VERSION ""

NS_ :

BS_:

BU_: IAP ODS _4WD BCM HUD DATC MDPS AAF_Tester AEMC SMK _4WD EPB CUBIS MTS TMU EVP CGW TPMS LPI DI_BOX SPAS EMS LCA TCU IBOX FATC AFLS FPCM SCC AHLS AVM ABS SNV OPI PGS SAS AAF Dummy LDWS_LKAS LVR ESC PSB CLU ECS ACU REA

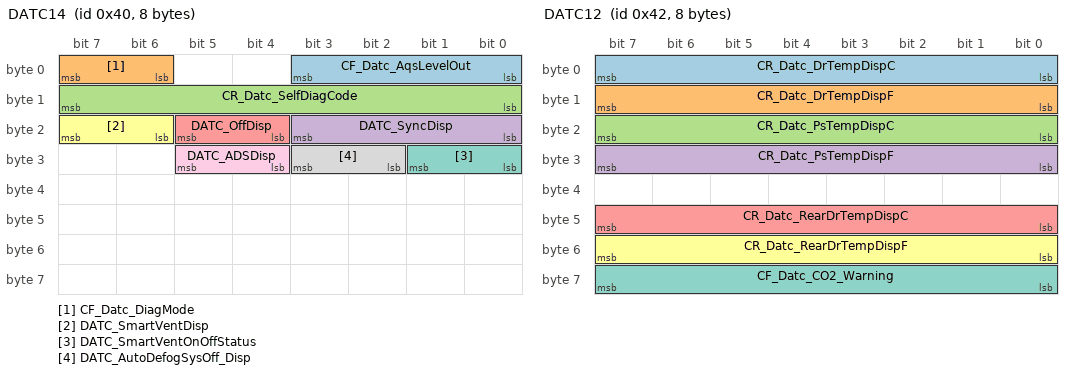
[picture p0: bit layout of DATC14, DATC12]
BO_ 64 DATC14: 8 DATC
 SG_ CF_Datc_AqsLevelOut : 0|4@1+ (1.0,0.0) [0.0|3.0] ""  CLU
 SG_ CF_Datc_DiagMode : 6|2@1+ (1.0,0.0) [0.0|3.0] ""  CLU
 SG_ CR_Datc_SelfDiagCode : 8|8@1+ (1.0,-1.0) [0.0|254.0] ""  CLU
 SG_ DATC_SyncDisp : 16|4@1+ (1.0,0.0) [0.0|3.0] ""  CLU
 SG_ DATC_OffDisp : 20|2@1+ (1.0,0.0) [0.0|3.0] ""  CLU
 SG_ DATC_SmartVentDisp : 22|2@1+ (1.0,0.0) [0.0|3.0] ""  CLU
 SG_ DATC_SmartVentOnOffStatus : 24|2@1+ (1.0,0.0) [0.0|3.0] ""  CLU
 SG_ DATC_AutoDefogSysOff_Disp : 26|2@1+ (1.0,0.0) [0.0|3.0] ""  CLU
 SG_ DATC_ADSDisp : 28|2@1+ (1.0,0.0) [0.0|3.0] ""  CLU

BO_ 66 DATC12: 8 DATC
 SG_ CR_Datc_DrTempDispC : 0|8@1+ (0.5,14.0) [15.0|32.0] "deg"  CLU,IBOX
 SG_ CR_Datc_DrTempDispF : 8|8@1+ (1.0,56.0) [58.0|90.0] "deg"  CLU,IBOX
 SG_ CR_Datc_PsTempDispC : 16|8@1+ (0.5,14.0) [15.0|32.0] "deg"  CLU,IBOX
 SG_ CR_Datc_PsTempDispF : 24|8@1+ (1.0,56.0) [58.0|90.0] "deg"  CLU,IBOX
 SG_ CR_Datc_RearDrTempDispC : 40|8@1+ (0.5,14.0) [15.0|32.0] "deg"  CLU
 SG_ CR_Datc_RearDrTempDispF : 48|8@1+ (1.0,58.0) [58.0|90.0] "deg"  CLU
 SG_ CF_Datc_CO2_Warning : 56|8@1+ (1.0,0.0) [0.0|3.0] ""  CLU

BO_ 67 DATC13: 8 DATC
 SG_ CF_Datc_TempDispUnit : 0|2@1+ (1.0,0.0) [0.0|3.0] ""  CLU,IBOX
 SG_ CF_Datc_ModDisp : 2|4@1+ (1.0,0.0) [0.0|15.0] ""  CLU
 SG_ CF_Datc_IonClean : 6|2@1+ (1.0,0.0) [0.0|3.0] ""  CLU
 SG_ CF_Datc_ChgReqDisp : 8|2@1+ (1.0,0.0) [0.0|3.0] ""  CLU
 SG_ CF_Datc_IntakeDisp : 10|2@1+ (1.0,0.0) [0.0|3.0] ""  CLU
 SG_ CF_Datc_AutoDisp : 12|2@1+ (1.0,0.0) [0.0|3.0] ""  CLU
 SG_ CF_Datc_FrDefLed : 14|2@1+ (1.0,0.0) [0.0|3.0] ""  CLU,IBOX
 SG_ CF_Datc_AutoDefogBlink : 16|2@1+ (1.0,0.0) [0.0|3.0] ""  CLU
 SG_ CF_Datc_ClmScanDisp : 18|2@1+ (1.0,0.0) [0.0|3.0] ""  CLU
 SG_ CF_Datc_AqsDisp : 20|2@1+ (1.0,0.0) [0.0|3.0] ""  CLU
 SG_ CF_Datc_AcDisp : 22|2@1+ (1.0,0.0) [0.0|3.0] ""  CLU
 SG_ CF_Datc_OpSts : 25|3@1+ (1.0,0.0) [0.0|7.0] ""  CLU
 SG_ CF_Mtc_MaxAcDisp : 28|2@1+ (1.0,0.0) [0.0|3.0] ""  CLU
 SG_ CF_Datc_DualDisp : 30|2@1+ (1.0,0.0) [0.0|3.0] ""  CLU
 SG_ CF_Datc_PwrInf : 32|4@1+ (1.0,0.0) [0.0|15.0] ""  CLU
 SG_ CF_Datc_RearManual : 38|2@1+ (1.0,0.0) [0.0|3.0] ""  CLU
 SG_ CF_Datc_RearAutoDisp : 40|2@1+ (1.0,0.0) [0.0|1.0] ""  CLU
 SG_ CF_Datc_RearOffDisp : 42|2@1+ (1.0,0.0) [0.0|3.0] ""  CLU
 SG_ CF_Datc_RearClimateScnDisp : 44|2@1+ (1.0,0.0) [0.0|3.0] ""  CLU
 SG_ CF_Datc_RearChgReqDisp : 46|2@1+ (1.0,0.0) [0.0|3.0] ""  CLU
 SG_ CF_Datc_RearModDisp : 48|4@1+ (1.0,0.0) [0.0|15.0] ""  CLU
 SG_ CF_Datc_RearBlwDisp : 52|4@1+ (1.0,0.0) [0.0|15.0] ""  CLU
 SG_ CF_Datc_PSModDisp : 56|4@1+ (1.0,0.0) [0.0|15.0] ""  CLU
 SG_ CF_Datc_FrontBlwDisp : 60|4@1+ (1.0,0.0) [0.0|15.0] ""  CLU,IBOX

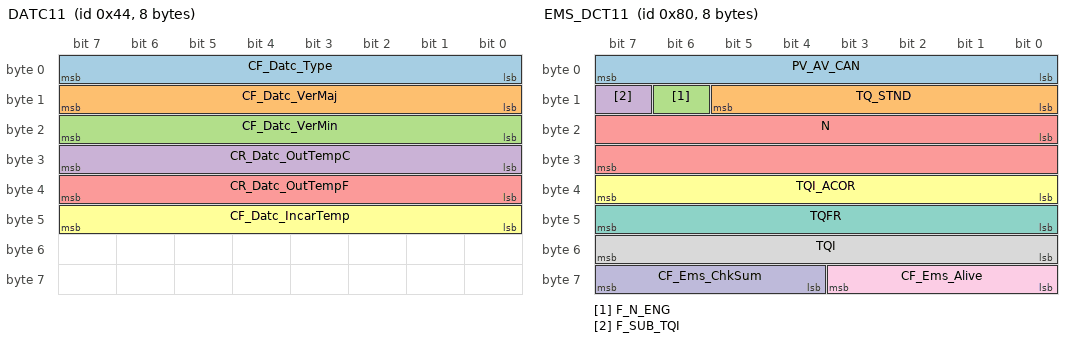
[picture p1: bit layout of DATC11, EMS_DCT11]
BO_ 68 DATC11: 8 DATC
 SG_ CF_Datc_Type : 0|8@1+ (1.0,0.0) [0.0|255.0] ""  CLU
 SG_ CF_Datc_VerMaj : 8|8@1+ (1.0,0.0) [0.0|255.0] ""  CLU
 SG_ CF_Datc_VerMin : 16|8@1+ (1.0,0.0) [0.0|255.0] ""  CLU
 SG_ CR_Datc_OutTempC : 24|8@1+ (0.5,-41.0) [-41.0|86.5] "deg"  CLU,FPCM
 SG_ CR_Datc_OutTempF : 32|8@1+ (1.0,-42.0) [-42.0|213.0] "deg"  CLU
 SG_ CF_Datc_IncarTemp : 40|8@1+ (0.5,-40.0) [-40.0|60.0] "deg"  BCM,CLU

BO_ 127 CGW5: 8 BCM
 SG_ C_StopLampLhOpenSts : 0|1@1+ (1.0,0.0) [0.0|1.0] ""  CLU
 SG_ C_StopLampRhOpenSts : 1|1@1+ (1.0,0.0) [0.0|1.0] ""  CLU
 SG_ C_HMSLOpenSts : 2|1@1+ (1.0,0.0) [0.0|1.0] ""  CLU
 SG_ C_HLampLowLhOpenSts : 3|1@1+ (1.0,0.0) [0.0|1.0] ""  CLU
 SG_ C_HLampLowRhOpenSts : 4|1@1+ (1.0,0.0) [0.0|1.0] ""  CLU
 SG_ C_HLampHighLhOpenSts : 5|1@1+ (1.0,0.0) [0.0|1.0] ""  CLU
 SG_ C_HLampHighRhOpenSts : 6|1@1+ (1.0,0.0) [0.0|1.0] ""  CLU
 SG_ C_DRLLampLhOpenSts : 7|1@1+ (1.0,0.0) [0.0|1.0] ""  CLU
 SG_ C_DRLLampRhOpenSts : 8|1@1+ (1.0,0.0) [0.0|1.0] ""  CLU
 SG_ C_RearFOGLhOpenSts : 9|1@1+ (1.0,0.0) [0.0|1.0] ""  CLU
 SG_ C_RearFOGRhOpenSts : 10|1@1+ (1.0,0.0) [0.0|1.0] ""  CLU
 SG_ C_FrontFOGLhOpenSts : 11|1@1+ (1.0,0.0) [0.0|1.0] ""  CLU
 SG_ C_FrontFOGRhOpenSts : 12|1@1+ (1.0,0.0) [0.0|1.0] ""  CLU
 SG_ C_RearEXTTailLhOpenSts : 13|1@1+ (1.0,0.0) [0.0|1.0] ""  CLU
 SG_ C_RearEXTTailRhOpenSts : 14|1@1+ (1.0,0.0) [0.0|1.0] ""  CLU
 SG_ C_FrontEXTTailLhOpenSts : 15|1@1+ (1.0,0.0) [0.0|1.0] ""  CLU
 SG_ C_FrontEXTTailRhOpenSts : 16|1@1+ (1.0,0.0) [0.0|1.0] ""  CLU
 SG_ C_RearTSIGLhOpenSts : 17|1@1+ (1.0,0.0) [0.0|1.0] ""  CLU
 SG_ C_RearTSIGRhOpenSts : 18|1@1+ (1.0,0.0) [0.0|1.0] ""  CLU
 SG_ C_FrontTSIGLhOpenSts : 19|1@1+ (1.0,0.0) [0.0|1.0] ""  CLU
 SG_ C_FrontTSIGRhOpenSts : 20|1@1+ (1.0,0.0) [0.0|1.0] ""  CLU
 SG_ C_SBendingLhOpenSts : 21|1@1+ (1.0,0.0) [0.0|1.0] ""  CLU
 SG_ C_SBendingRhOpenSts : 22|1@1+ (1.0,0.0) [0.0|1.0] ""  CLU
 SG_ C_LicensePlateLhOpenSts : 23|1@1+ (1.0,0.0) [0.0|1.0] ""  CLU
 SG_ C_LicensePlateRhOpenSts : 24|1@1+ (1.0,0.0) [0.0|1.0] ""  CLU

BO_ 128 EMS_DCT11: 8 EMS
 SG_ PV_AV_CAN : 0|8@1+ (0.3906,0.0) [0.0|99.603] "%"  TCU
 SG_ TQ_STND : 8|6@1+ (10.0,0.0) [0.0|630.0] "Nm"  TCU
 SG_ F_N_ENG : 14|1@1+ (1.0,0.0) [0.0|1.0] ""  TCU
 SG_ F_SUB_TQI : 15|1@1+ (1.0,0.0) [0.0|1.0] ""  TCU
 SG_ N : 16|16@1+ (0.25,0.0) [0.0|16383.75] "rpm"  TCU
 SG_ TQI_ACOR : 32|8@1+ (0.390625,0.0) [0.0|99.6094] "%"  IBOX,TCU
 SG_ TQFR : 40|8@1+ (0.390625,0.0) [0.0|99.6094] "%"  TCU
 SG_ TQI : 48|8@1+ (0.390625,0.0) [0.0|99.609375] "%"  TCU
 SG_ CF_Ems_Alive : 56|4@1+ (1.0,0.0) [0.0|15.0] ""  TCU
 SG_ CF_Ems_ChkSum : 60|4@1+ (1.0,0.0) [0.0|15.0] ""  TCU

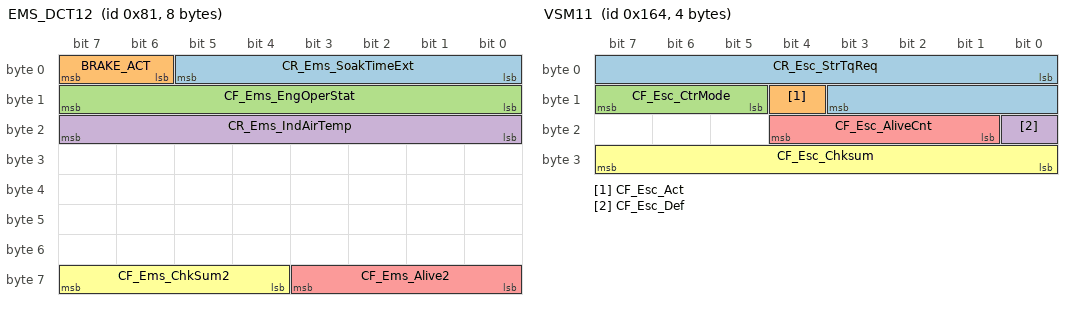
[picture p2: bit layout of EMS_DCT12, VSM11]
BO_ 129 EMS_DCT12: 8 EMS
 SG_ CR_Ems_SoakTimeExt : 0|6@1+ (5.0,0.0) [0.0|315.0] "Min"  TCU
 SG_ BRAKE_ACT : 6|2@1+ (1.0,0.0) [0.0|3.0] ""  TCU
 SG_ CF_Ems_EngOperStat : 8|8@1+ (1.0,0.0) [0.0|255.0] ""  TCU
 SG_ CR_Ems_IndAirTemp : 16|8@1+ (0.75,-48.0) [-48.0|143.25] "deg"  TCU
 SG_ CF_Ems_Alive2 : 56|4@1+ (1.0,0.0) [0.0|15.0] ""  TCU
 SG_ CF_Ems_ChkSum2 : 60|4@1+ (1.0,0.0) [0.0|15.0] ""  TCU

BO_ 339 TCS11: 8 ESC
 SG_ TCS_REQ : 0|1@1+ (1.0,0.0) [0.0|1.0] ""  _4WD,EMS,EPB,TCU
 SG_ MSR_C_REQ : 1|1@1+ (1.0,0.0) [0.0|1.0] ""  EMS,EPB,SCC,TCU
 SG_ TCS_PAS : 2|1@1+ (1.0,0.0) [0.0|1.0] ""  _4WD,CLU,EMS,SCC,SPAS,TCU
 SG_ TCS_GSC : 3|1@1+ (1.0,0.0) [0.0|1.0] ""  _4WD,EMS,TCU
 SG_ CF_Esc_LimoInfo : 4|2@1+ (1.0,0.0) [0.0|3.0] ""  _4WD,SCC
 SG_ ABS_DIAG : 6|1@1+ (1.0,0.0) [0.0|1.0] ""  _4WD,CLU,EMS,EPB
 SG_ ABS_DEF : 7|1@1+ (1.0,0.0) [0.0|1.0] ""  _4WD,ACU,ECS,EMS,EPB,SCC,SPAS,TCU
 SG_ TCS_DEF : 8|1@1+ (1.0,0.0) [0.0|1.0] ""  _4WD,EMS,EPB,SCC,SPAS,TCU
 SG_ TCS_CTL : 9|1@1+ (1.0,0.0) [0.0|1.0] ""  _4WD,EMS,EPB,SCC,SPAS,TCU
 SG_ ABS_ACT : 10|1@1+ (1.0,0.0) [0.0|1.0] ""  _4WD,ACU,ECS,EMS,EPB,LDWS_LKAS,SCC,SPAS,TCU
 SG_ EBD_DEF : 11|1@1+ (1.0,0.0) [0.0|1.0] ""  _4WD,EMS,EPB,SPAS,TCU
 SG_ ESP_PAS : 12|1@1+ (1.0,0.0) [0.0|1.0] ""  _4WD,ACU,CLU,EMS,EPB,LDWS_LKAS,SCC,TCU
 SG_ ESP_DEF : 13|1@1+ (1.0,0.0) [0.0|1.0] ""  _4WD,ACU,ECS,EMS,EPB,LDWS_LKAS,SCC,TCU
 SG_ ESP_CTL : 14|1@1+ (1.0,0.0) [0.0|1.0] ""  _4WD,ACU,ECS,EMS,EPB,LDWS_LKAS,SCC,SPAS,TCU
 SG_ TCS_MFRN : 15|1@1+ (1.0,0.0) [0.0|1.0] ""  EMS,EPB,TCU
 SG_ DBC_CTL : 16|1@1+ (1.0,0.0) [0.0|1.0] ""  _4WD,EMS,EPB
 SG_ DBC_PAS : 17|1@1+ (1.0,0.0) [0.0|1.0] ""  _4WD,EMS,EPB
 SG_ DBC_DEF : 18|1@1+ (1.0,0.0) [0.0|1.0] ""  _4WD,EMS,EPB
 SG_ HAC_CTL : 19|1@1+ (1.0,0.0) [0.0|1.0] ""  _4WD,CLU,EMS,EPB,TCU
 SG_ HAC_PAS : 20|1@1+ (1.0,0.0) [0.0|1.0] ""  _4WD,CLU,EMS,EPB,TCU
 SG_ HAC_DEF : 21|1@1+ (1.0,0.0) [0.0|1.0] ""  _4WD,CLU,EMS,EPB,TCU
 SG_ ESS_STAT : 22|2@1+ (1.0,0.0) [0.0|3.0] ""  _4WD,BCM,CLU,EMS,EPB
 SG_ TQI_TCS : 24|8@1+ (0.390625,0.0) [0.0|99.609375] "%"  EMS,EPB,TCU
 SG_ TQI_MSR : 32|8@1+ (0.390625,0.0) [0.0|99.609375] "%"  EMS,EPB,TCU
 SG_ TQI_SLW_TCS : 40|8@1+ (0.390625,0.0) [0.0|99.609375] "%"  EMS,EPB,TCU
 SG_ CF_Esc_BrkCtl : 48|1@1+ (1.0,0.0) [0.0|1.0] ""  EMS
 SG_ BLA_CTL : 49|2@1+ (1.0,0.0) [0.0|3.0] ""  BCM,CGW,CLU
 SG_ AliveCounter_TCS1 : 52|4@1+ (1.0,0.0) [0.0|14.0] ""  EMS,EPB,LDWS_LKAS
 SG_ CheckSum_TCS1 : 56|8@1+ (1.0,0.0) [0.0|255.0] ""  EMS,EPB,LDWS_LKAS

BO_ 356 VSM11: 4 ESC
 SG_ CR_Esc_StrTqReq : 0|12@1+ (0.01,-20.48) [-20.48|20.47] "Nm"  MDPS
 SG_ CF_Esc_Act : 12|1@1+ (1.0,0.0) [0.0|1.0] ""  LDWS_LKAS,MDPS
 SG_ CF_Esc_CtrMode : 13|3@1+ (1.0,0.0) [0.0|7.0] ""  MDPS
 SG_ CF_Esc_Def : 16|1@1+ (1.0,0.0) [0.0|1.0] ""  MDPS
 SG_ CF_Esc_AliveCnt : 17|4@1+ (1.0,0.0) [0.0|15.0] ""  LDWS_LKAS,MDPS
 SG_ CF_Esc_Chksum : 24|8@1+ (1.0,0.0) [0.0|255.0] ""  LDWS_LKAS,MDPS

BO_ 399 EMS_H12: 8 EMS
 SG_ R_TqAcnApvC : 0|8@1+ (0.2,0.0) [0.0|51.0] "Nm"  DATC,IBOX
 SG_ R_PAcnC : 8|8@1+ (125.0,0.0) [0.0|31875.0] "hPa"  DATC,IBOX
 SG_ TQI_B : 16|8@1+ (0.390625,0.0) [0.0|99.609375] "%"  ABS,ESC,IBOX
 SG_ SLD_VS : 24|8@1+ (1.0,0.0) [0.0|255.0] "km/h"  CLU,IBOX
 SG_ CF_CdaStat : 32|3@1+ (1.0,0.0) [0.0|7.0] ""  AEMC,IBOX,TCU
 SG_ CF_Ems_IsgStat : 35|3@1+ (1.0,0.0) [0.0|7.0] ""  ABS,BCM,CLU,DATC,EPB,ESC,IBOX,LDWS_LKAS,MDPS,SMK,TCU
 SG_ CF_Ems_OilChg : 38|1@1+ (1.0,0.0) [0.0|1.0] ""  CLU,IBOX
 SG_ CF_Ems_EtcLimpMod : 39|1@1+ (1.0,0.0) [0.0|1.0] ""  CLU,IBOX
 SG_ R_NEngIdlTgC : 40|8@1+ (10.0,0.0) [0.0|2550.0] "rpm"  DATC,IBOX,TCU
 SG_ CF_Ems_UpTarGr : 48|1@1+ (1.0,0.0) [0.0|1.0] ""  CLU,IBOX
 SG_ CF_Ems_DownTarGr : 49|1@1+ (1.0,0.0) [0.0|1.0] ""  CLU,IBOX
 SG_ CF_Ems_DesCurGr : 50|4@1+ (1.0,0.0) [0.0|15.0] ""  CLU,IBOX
 SG_ CF_Ems_SldAct : 54|1@1+ (1.0,0.0) [0.0|1.0] ""  CLU,IBOX
 SG_ CF_Ems_SldPosAct : 55|1@1+ (1.0,0.0) [0.0|1.0] ""  CLU,IBOX
 SG_ CF_Ems_HPresStat : 56|1@1+ (1.0,0.0) [0.0|1.0] ""  IBOX,TCU
 SG_ CF_Ems_IsgBuz : 57|1@1+ (1.0,0.0) [0.0|1.0] ""  CLU,IBOX
 SG_ CF_Ems_IdlStpFCO : 58|1@1+ (1.0,0.0) [0.0|1.0] ""  CLU,IBOX
 SG_ CF_Ems_FCopen : 59|1@1+ (1.0,0.0) [0.0|1.0] ""  CLU,IBOX
 SG_ CF_Ems_ActEcoAct : 60|1@1+ (1.0,0.0) [0.0|1.0] ""  CLU,IBOX,TCU
 SG_ CF_Ems_EngRunNorm : 61|1@1+ (1.0,0.0) [0.0|1.0] ""  ABS,ESC,IBOX,TCU
 SG_ CF_Ems_IsgStat2 : 62|2@1+ (2.0,0.0) [0.0|3.0] ""  CLU,IBOX,TCU

BO_ 447 ???: 8 ???

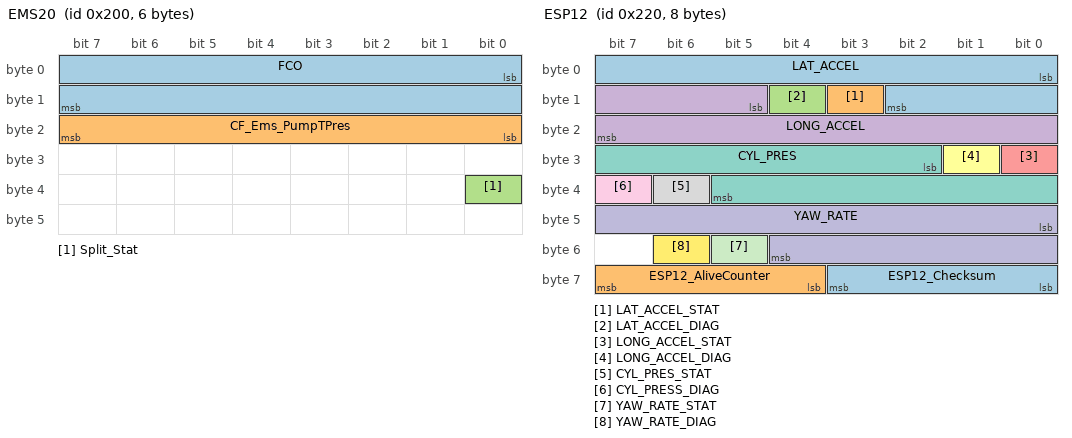
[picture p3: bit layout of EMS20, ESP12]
BO_ 512 EMS20: 6 EMS
 SG_ FCO : 0|16@1+ (0.128,0.0) [0.0|8388.48] "ul"  CLU,CUBIS,FPCM,IBOX
 SG_ CF_Ems_PumpTPres : 16|8@1+ (3.137254902,0.0) [0.0|800.0] "kPa"  FPCM,IBOX
 SG_ Split_Stat : 32|1@1+ (1.0,0.0) [0.0|1.0] ""  FPCM

BO_ 544 ESP12: 8 ESC
 SG_ LAT_ACCEL : 0|11@1+ (0.01,-10.23) [-10.23|10.24] "m/s^2"  _4WD,ECS,IBOX,LCA,LDWS_LKAS,MDPS,PSB,SCC,TCU
 SG_ LAT_ACCEL_STAT : 11|1@1+ (1.0,0.0) [0.0|1.0] ""  _4WD,IBOX,LDWS_LKAS,MDPS,PSB,SCC,TCU
 SG_ LAT_ACCEL_DIAG : 12|1@1+ (1.0,0.0) [0.0|1.0] ""  _4WD,IBOX,LDWS_LKAS,MDPS,PSB,SCC,TCU
 SG_ LONG_ACCEL : 13|11@1+ (0.01,-10.23) [-10.23|10.24] "m/s^2"  _4WD,ECS,EMS,EPB,IBOX,LCA,LDWS_LKAS,PSB,SCC,SPAS,TCU
 SG_ LONG_ACCEL_STAT : 24|1@1+ (1.0,0.0) [0.0|1.0] ""  _4WD,EMS,EPB,IBOX,LDWS_LKAS,PSB,SCC,SPAS,TCU
 SG_ LONG_ACCEL_DIAG : 25|1@1+ (1.0,0.0) [0.0|1.0] ""  _4WD,EMS,EPB,IBOX,LDWS_LKAS,PSB,SCC,SPAS,TCU
 SG_ CYL_PRES : 26|12@1+ (0.1,0.0) [0.0|409.5] "Bar"  _4WD,ECS,EMS,EPB,IBOX,LDWS_LKAS,PSB,SCC,TCU
 SG_ CYL_PRES_STAT : 38|1@1+ (1.0,0.0) [0.0|1.0] ""  _4WD,ECS,EMS,EPB,IBOX,LDWS_LKAS,PSB,SCC,TCU
 SG_ CYL_PRESS_DIAG : 39|1@1+ (1.0,0.0) [0.0|1.0] ""  _4WD,ECS,EMS,EPB,IBOX,PSB,SCC,TCU
 SG_ YAW_RATE : 40|13@1+ (0.01,-40.95) [-40.95|40.96] ""  _4WD,AFLS,IBOX,LCA,LDWS_LKAS,MDPS,PSB,SCC,SPAS,TCU
 SG_ YAW_RATE_STAT : 53|1@1+ (1.0,0.0) [0.0|1.0] ""  _4WD,AFLS,IBOX,LCA,LDWS_LKAS,MDPS,PSB,SCC,SPAS,TCU
 SG_ YAW_RATE_DIAG : 54|1@1+ (1.0,0.0) [0.0|1.0] ""  _4WD,AFLS,IBOX,LCA,LDWS_LKAS,MDPS,PSB,SCC,SPAS,TCU
 SG_ ESP12_Checksum : 56|4@1+ (1.0,0.0) [0.0|15.0] ""  _4WD,EMS,LPI,TCU,TMU
 SG_ ESP12_AliveCounter : 60|4@1+ (1.0,0.0) [0.0|15.0] ""  _4WD,EMS,LPI,TCU,TMU

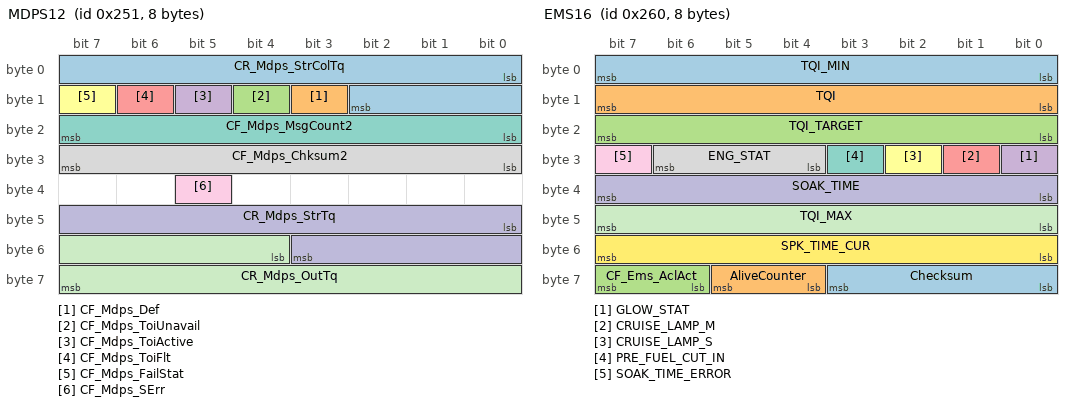
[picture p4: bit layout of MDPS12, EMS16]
BO_ 593 MDPS12: 8 MDPS
 SG_ CR_Mdps_StrColTq : 0|11@1+ (1.0,-1024.0) [-1024.0|1024.0] ""  LDWS_LKAS
 SG_ CF_Mdps_Def : 11|1@1+ (1.0,0.0) [0.0|1.0] ""  ESC
 SG_ CF_Mdps_ToiUnavail : 12|1@1+ (1.0,0.0) [0.0|1.0] ""  LDWS_LKAS
 SG_ CF_Mdps_ToiActive : 13|1@1+ (1.0,0.0) [0.0|1.0] ""  LDWS_LKAS
 SG_ CF_Mdps_ToiFlt : 14|1@1+ (1.0,0.0) [0.0|1.0] ""  LDWS_LKAS
 SG_ CF_Mdps_FailStat : 15|1@1+ (1.0,0.0) [0.0|1.0] ""  LDWS_LKAS
 SG_ CF_Mdps_MsgCount2 : 16|8@1+ (1.0,0.0) [0.0|255.0] ""  ESC,LDWS_LKAS
 SG_ CF_Mdps_Chksum2 : 24|8@1+ (1.0,0.0) [0.0|255.0] ""  ESC,LDWS_LKAS
 SG_ CF_Mdps_SErr : 37|1@1+ (1.0,0.0) [0.0|1.0] ""  ESC
 SG_ CR_Mdps_StrTq : 40|12@1+ (0.01,-20.48) [-20.48|20.47] "Nm"  ESC
 SG_ CR_Mdps_OutTq : 52|12@1+ (0.1,-204.8) [-204.8|204.7] ""  ESC,LDWS_LKAS

BO_ 608 EMS16: 8 EMS
 SG_ TQI_MIN : 0|8@1+ (0.390625,0.0) [0.0|99.609375] "%"  ESC,IBOX,TCU
 SG_ TQI : 8|8@1+ (0.390625,0.0) [0.0|99.609375] "%"  ESC,IBOX,TCU
 SG_ TQI_TARGET : 16|8@1+ (0.390625,0.0) [0.0|99.609375] "%"  EPB,ESC,IBOX,TCU
 SG_ GLOW_STAT : 24|1@1+ (1.0,0.0) [0.0|1.0] ""  BCM,CLU,IBOX,SMK
 SG_ CRUISE_LAMP_M : 25|1@1+ (1.0,0.0) [0.0|1.0] ""  CLU,IBOX,TCU
 SG_ CRUISE_LAMP_S : 26|1@1+ (1.0,0.0) [0.0|1.0] ""  CLU,IBOX,TCU
 SG_ PRE_FUEL_CUT_IN : 27|1@1+ (1.0,0.0) [0.0|1.0] ""  IBOX,TCU
 SG_ ENG_STAT : 28|3@1+ (1.0,0.0) [0.0|7.0] ""  ABS,AHLS,AVM,BCM,CLU,EPB,ESC,EVP,FPCM,IBOX,LCA,LDWS_LKAS,MDPS,SCC,SMK,TCU
 SG_ SOAK_TIME_ERROR : 31|1@1+ (1.0,0.0) [0.0|1.0] ""  DATC,EPB,IBOX,TCU
 SG_ SOAK_TIME : 32|8@1+ (1.0,0.0) [0.0|255.0] "Min"  _4WD,DATC,EPB,IBOX,TCU
 SG_ TQI_MAX : 40|8@1+ (0.390625,0.0) [0.0|99.609375] "%"  ESC,IBOX,TCU
 SG_ SPK_TIME_CUR : 48|8@1+ (0.375,-35.625) [-35.625|60.0] ""  IBOX,TCU
 SG_ Checksum : 56|4@1+ (1.0,0.0) [0.0|15.0] ""  ECS,IBOX,LDWS_LKAS,MDPS,SCC
 SG_ AliveCounter : 60|2@1+ (1.0,0.0) [0.0|3.0] ""  IBOX,LDWS_LKAS,MDPS,SCC
 SG_ CF_Ems_AclAct : 62|2@1+ (1.0,0.0) [0.0|3.0] ""  IBOX,SCC

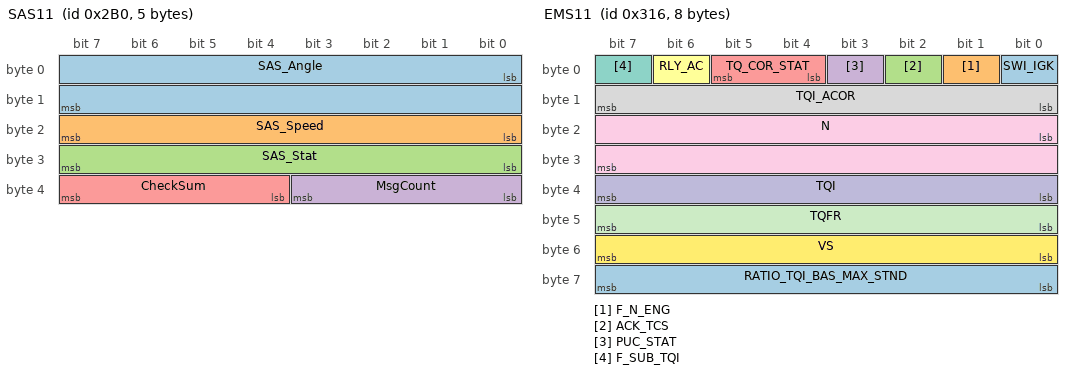
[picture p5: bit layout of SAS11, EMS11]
BO_ 688 SAS11: 5 MDPS
 SG_ SAS_Angle : 0|16@1- (0.1,0.0) [-3276.8|3276.7] "Deg"  _4WD,ACU,AFLS,AVM,CLU,ECS,EMS,ESC,IBOX,LCA,LDWS_LKAS,PGS,PSB,SCC,SPAS,TCU,_4WD,ACU,AFLS,AVM,BCM,CLU,ECS,EMS,ESC,IBOX,LCA,LDWS_LKAS,PGS,PSB,SCC,SPAS,TCU
 SG_ SAS_Speed : 16|8@1+ (4.0,0.0) [0.0|1016.0] ""  AFLS,ECS,ESC,IBOX,LDWS_LKAS,SCC,SPAS,TCU,AFLS,ECS,ESC,IBOX,LDWS_LKAS,SCC,SPAS,TCU
 SG_ SAS_Stat : 24|8@1+ (1.0,0.0) [0.0|255.0] ""  ECS,ESC,IBOX,LDWS_LKAS,PSB,SCC,SPAS,TCU,ECS,ESC,IBOX,LDWS_LKAS,PSB,SCC,SPAS,TCU
 SG_ MsgCount : 32|4@1+ (1.0,0.0) [0.0|15.0] ""  ECS,ESC,IBOX,LDWS_LKAS,PSB,SCC,SPAS,ECS,ESC,IBOX,LDWS_LKAS,PSB,SCC,SPAS
 SG_ CheckSum : 36|4@1+ (1.0,0.0) [0.0|15.0] ""  ECS,EMS,ESC,IBOX,LDWS_LKAS,PSB,SCC,SPAS,ECS,EMS,ESC,IBOX,LDWS_LKAS,PSB,SCC,SPAS

BO_ 764 ???: 8 ??
 SG_ Drive_Mode_Command : 56|4@0+ (0.0,0.0) [0.0|15] ""  ??

BO_ 781 ???: 6 ??

BO_ 790 EMS11: 8 EMS
 SG_ SWI_IGK : 0|1@1+ (1.0,0.0) [0.0|1.0] ""  _4WD,ABS,ACU,AHLS,CUBIS,DI_BOX,ECS,EPB,ESC,IBOX,LDWS_LKAS,MDPS,REA,SAS,SCC,TCU
 SG_ F_N_ENG : 1|1@1+ (1.0,0.0) [0.0|1.0] ""  _4WD,ACU,AFLS,CLU,CUBIS,DATC,ECS,EPB,ESC,IBOX,MDPS,SCC,TCU
 SG_ ACK_TCS : 2|1@1+ (1.0,0.0) [0.0|1.0] ""  ESC,IBOX
 SG_ PUC_STAT : 3|1@1+ (1.0,0.0) [0.0|1.0] ""  _4WD,CLU,DATC,IBOX,TCU
 SG_ TQ_COR_STAT : 4|2@1+ (1.0,0.0) [0.0|3.0] ""  _4WD,ESC,IBOX,TCU
 SG_ RLY_AC : 6|1@1+ (1.0,0.0) [0.0|1.0] ""  DATC,IBOX,TCU
 SG_ F_SUB_TQI : 7|1@1+ (1.0,0.0) [0.0|1.0] ""  _4WD,ECS,EPB,ESC,IBOX,TCU
 SG_ TQI_ACOR : 8|8@1+ (0.390625,0.0) [0.0|99.6094] "%"  _4WD,EPB,ESC,IBOX,TCU
 SG_ N : 16|16@1+ (0.25,0.0) [0.0|16383.75] "rpm"  _4WD,ACU,AFLS,CLU,CUBIS,DATC,ECS,EPB,ESC,FPCM,IBOX,MDPS,SCC,TCU
 SG_ TQI : 32|8@1+ (0.390625,0.0) [0.0|99.6094] "%"  _4WD,ECS,EPB,ESC,IBOX,TCU
 SG_ TQFR : 40|8@1+ (0.390625,0.0) [0.0|99.6094] "%"  _4WD,EPB,ESC,IBOX,TCU
 SG_ VS : 48|8@1+ (1.0,0.0) [0.0|254.0] "km/h"  _4WD,AAF,ACU,AHLS,BCM,CLU,DATC,ECS,EPB,IBOX,LCA,LDWS_LKAS,LVR,MDPS,ODS,SCC,SMK,SPAS,TCU,TPMS
 SG_ RATIO_TQI_BAS_MAX_STND : 56|8@1+ (0.0078,0.0) [0.0|2.0] ""  _4WD,IBOX,TCU

BO_ 809 EMS12: 8 EMS
 SG_ CONF_TCU m1 : 0|6@1+ (1.0,0.0) [0.0|63.0] ""  _4WD,ACU,BCM,CLU,DATC,EPB,ESC,IBOX,LCA,SMK
 SG_ CAN_VERS m0 : 0|6@1+ (1.0,0.0) [0.0|7.7] ""  _4WD,ABS,ESC,IBOX
 SG_ TQ_STND m3 : 0|6@1+ (10.0,0.0) [0.0|630.0] "Nm"  _4WD,DATC,ECS,EPB,ESC,FATC,IBOX
 SG_ OBD_FRF_ACK m2 : 0|6@1+ (1.0,0.0) [0.0|63.0] ""  _4WD,ESC,IBOX
 SG_ MUL_CODE M : 6|2@1+ (1.0,0.0) [0.0|3.0] ""  _4WD,ABS,ACU,BCM,CLU,DATC,ECS,EPB,ESC,IBOX,LCA,SMK,TCU
 SG_ TEMP_ENG : 8|8@1+ (0.75,-48.0) [-48.0|143.25] "deg"  _4WD,BCM,CLU,DATC,EPB,ESC,IBOX,SMK,TCU
 SG_ MAF_FAC_ALTI_MMV : 16|8@1+ (0.00781,0.0) [0.0|1.99155] ""  IBOX,TCU
 SG_ VB_OFF_ACT : 24|1@1+ (1.0,0.0) [0.0|1.0] ""  IBOX,TCU
 SG_ ACK_ES : 25|1@1+ (1.0,0.0) [0.0|1.0] ""  _4WD,ACU,IBOX
 SG_ CONF_MIL_FMY : 26|3@1+ (1.0,0.0) [0.0|7.0] ""  ESC,IBOX,TCU
 SG_ OD_OFF_REQ : 29|1@1+ (1.0,0.0) [0.0|1.0] ""  IBOX,TCU
 SG_ ACC_ACT : 30|1@1+ (1.0,0.0) [0.0|1.0] ""  _4WD,ABS,CLU,ESC,IAP,IBOX,SCC,TCU
 SG_ CLU_ACK : 31|1@1+ (1.0,0.0) [0.0|1.0] ""  _4WD,EPB,ESC,IBOX
 SG_ BRAKE_ACT : 32|2@1+ (1.0,0.0) [0.0|3.0] ""  _4WD,ABS,ACU,AFLS,CLU,DATC,ECS,EPB,ESC,IBOX,LDWS_LKAS,TCU
 SG_ ENG_CHR : 34|4@1+ (1.0,0.0) [0.0|15.0] ""  _4WD,ABS,ACU,CLU,DATC,EPB,ESC,FATC,IBOX,SCC,SMK,TCU
 SG_ GP_CTL : 38|2@1+ (1.0,0.0) [0.0|3.0] ""  IBOX
 SG_ TPS : 40|8@1+ (0.4694836,-15.0234742) [-15.0234742|104.6948357] "%"  _4WD,ABS,ACU,CLU,DATC,ECS,EPB,ESC,IBOX,TCU
 SG_ PV_AV_CAN : 48|8@1+ (0.3906,0.0) [0.0|99.603] "%"  _4WD,AAF,ABS,ACU,AFLS,CLU,DATC,EPB,ESC,IAP,IBOX,LDWS_LKAS,SCC,TCU
 SG_ ENG_VOL : 56|8@1+ (0.1,0.0) [0.0|25.5] "liter"  _4WD,ABS,ACU,BCM,CLU,DATC,EPB,ESC,IBOX,LDWS_LKAS,SCC,SMK

BO_ 832 LKAS11: 8 LDWS_LKAS
 SG_ CF_Lkas_LdwsActivemode : 0|2@1+ (1,0) [0|3] "" CLU,IBOX,PSB
 SG_ CF_Lkas_LdwsSysState : 2|4@1+ (1.0,0.0) [0.0|15.0] ""  CLU,IBOX,PSB
 SG_ CF_Lkas_SysWarning : 6|4@1+ (1.0,0.0) [0.0|15.0] ""  BCM,CLU
 SG_ CF_Lkas_LdwsLHWarning : 10|2@1+ (1.0,0.0) [0.0|3.0] ""  BCM,CLU,PSB
 SG_ CF_Lkas_LdwsRHWarning : 12|2@1+ (1.0,0.0) [0.0|3.0] ""  BCM,CLU,PSB
 SG_ CF_Lkas_HbaLamp : 14|1@1+ (1.0,0.0) [0.0|1.0] ""  CLU
 SG_ CF_Lkas_FcwBasReq : 15|1@1+ (1.0,0.0) [0.0|1.0] ""  ABS,ESC
 SG_ CR_Lkas_StrToqReq : 16|11@1+ (1.0,-1024.0) [-1024.0|1024.0] ""  MDPS
 SG_ CF_Lkas_ActToi : 27|1@1+ (1.0,0.0) [0.0|1.0] ""  MDPS
 SG_ CF_Lkas_ToiFlt : 28|1@1+ (1.0,0.0) [0.0|1.0] ""  MDPS
 SG_ CF_Lkas_HbaSysState : 29|3@1+ (1.0,0.0) [0.0|7.0] ""  BCM,CLU
 SG_ CF_Lkas_FcwOpt : 32|2@1+ (1.0,0.0) [0.0|3.0] ""  CLU
 SG_ CF_Lkas_HbaOpt : 34|2@1+ (1.0,0.0) [0.0|1.0] ""  BCM,CGW
 SG_ CF_Lkas_MsgCount : 36|4@1+ (1.0,0.0) [0.0|15.0] ""  CLU,MDPS
 SG_ CF_Lkas_FcwSysState : 40|3@1+ (1.0,0.0) [0.0|7.0] ""  CLU
 SG_ CF_Lkas_FcwCollisionWarning : 43|2@1+ (1.0,0.0) [0.0|3.0] ""  CLU
 SG_ CF_Lkas_FusionState : 45|2@1+ (1.0,0.0) [0.0|3.0] ""  SCC
 SG_ CF_Lkas_Unknown1 : 47|1@1+ (1.0,0.0) [0.0|1.0] "" XXX
 SG_ CF_Lkas_Chksum : 48|8@1+ (1.0,0.0) [0.0|255.0] ""  MDPS
 SG_ CF_Lkas_FcwOpt_USM : 56|3@1+ (1.0,0.0) [0.0|7.0] ""  CLU
 SG_ CF_Lkas_LdwsOpt_USM : 59|3@1+ (1.0,0.0) [0.0|7.0] ""  CLU,MDPS
 SG_ CF_Lkas_Unknown2 : 62|2@1+ (1.0,0.0) [0.0|1.0] "" XXX

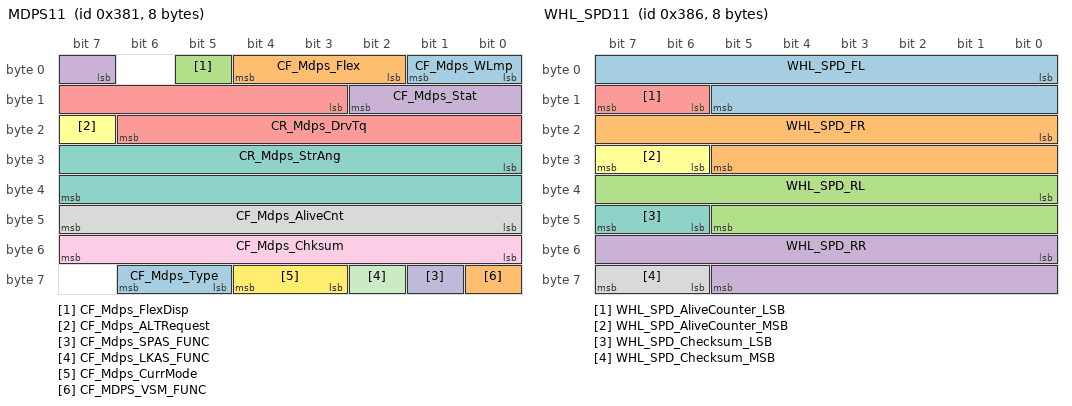
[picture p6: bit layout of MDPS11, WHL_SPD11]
BO_ 897 MDPS11: 8 MDPS
 SG_ CF_Mdps_WLmp : 0|2@1+ (1.0,0.0) [0.0|3.0] ""  CLU,CUBIS,EMS,IBOX,SPAS
 SG_ CF_Mdps_Flex : 2|3@1+ (1.0,0.0) [0.0|3.0] ""  CLU,LDWS_LKAS
 SG_ CF_Mdps_FlexDisp : 5|1@1+ (1.0,0.0) [0.0|1.0] ""  CLU
 SG_ CF_Mdps_Stat : 7|4@1+ (1.0,0.0) [0.0|15.0] ""  SPAS
 SG_ CR_Mdps_DrvTq : 11|12@1+ (1.0,-2048.0) [-2048.0|2046.0] ""  SPAS
 SG_ CF_Mdps_ALTRequest : 23|1@1+ (1.0,0.0) [0.0|1.0] ""  EMS
 SG_ CR_Mdps_StrAng : 24|16@1- (0.1,0.0) [-3276.8|3276.7] "Deg"  SPAS
 SG_ CF_Mdps_AliveCnt : 40|8@1+ (1.0,0.0) [0.0|255.0] ""  LDWS_LKAS,SPAS
 SG_ CF_Mdps_Chksum : 48|8@1+ (1.0,0.0) [0.0|255.0] ""  LDWS_LKAS,SPAS
 SG_ CF_Mdps_SPAS_FUNC : 57|1@1+ (1.0,0.0) [0.0|1.0] "flag"  SPAS
 SG_ CF_Mdps_LKAS_FUNC : 58|1@1+ (1.0,0.0) [0.0|1.0] "flag"  LDWS_LKAS
 SG_ CF_Mdps_CurrMode : 59|2@1+ (1.0,0.0) [0.0|3.0] ""  LDWS_LKAS
 SG_ CF_Mdps_Type : 61|2@1+ (1.0,0.0) [0.0|2.0] ""  LDWS_LKAS,SPAS
 SG_ CF_MDPS_VSM_FUNC : 56|1@0+ (1.0,0.0) [0.0|1.0] "" XXX

BO_ 899 FATC11: 8 DATC
 SG_ CR_Fatc_TqAcnOut : 0|8@1+ (0.2,0.0) [0.0|50.8] "Nm"  EMS,IBOX
 SG_ CF_Fatc_AcnRqSwi : 8|1@1+ (1.0,0.0) [0.0|1.0] ""  AAF,EMS,IBOX
 SG_ CF_Fatc_AcnCltEnRq : 9|1@1+ (1.0,0.0) [0.0|1.0] ""  EMS,IBOX
 SG_ CF_Fatc_EcvFlt : 10|1@1+ (1.0,0.0) [0.0|1.0] ""  EMS,IBOX
 SG_ CF_Fatc_BlwrOn : 11|1@1+ (1.0,0.0) [0.0|1.0] ""  EMS,IBOX
 SG_ CF_FATC_Iden : 12|2@1+ (1.0,0.0) [0.0|3.0] ""  EMS,IBOX
 SG_ CF_Fatc_BlwrMax : 14|1@1+ (1.0,0.0) [0.0|1.0] ""  CLU,EMS,IBOX
 SG_ CF_Fatc_EngStartReq : 15|1@1+ (1.0,0.0) [0.0|1.0] ""  EMS,IBOX
 SG_ CF_Fatc_IsgStopReq : 16|1@1+ (1.0,0.0) [0.0|1.0] ""  EMS,IBOX
 SG_ CF_Fatc_CtrInf : 17|3@1+ (1.0,0.0) [0.0|7.0] ""  EMS,IBOX
 SG_ CF_Fatc_MsgCnt : 20|4@1+ (1.0,0.0) [0.0|15.0] ""  EMS,IBOX
 SG_ CR_Fatc_OutTemp : 24|8@1+ (0.5,-40.0) [-40.0|60.0] "deg"  BCM,CLU,EMS,IBOX,SPAS,TCU,TPMS
 SG_ CR_Fatc_OutTempSns : 32|8@1+ (0.5,-40.0) [-40.0|60.0] "deg"  AAF,AHLS,CLU,EMS,IBOX,SPAS,TCU
 SG_ CF_Fatc_Compload : 40|3@1+ (1.0,0.0) [0.0|7.0] ""  EMS,IBOX
 SG_ CF_Fatc_ActiveEco : 43|1@1+ (1.0,0.0) [0.0|1.0] ""  CLU,IBOX
 SG_ CF_Fatc_AutoActivation : 44|1@1+ (1.0,0.0) [0.0|1.0] ""  IBOX
 SG_ CF_Fatc_DefSw : 45|1@1+ (1.0,0.0) [0.0|1.0] ""  BCM,IBOX
 SG_ CF_Fatc_PtcRlyStat : 46|1@1+ (1.0,0.0) [0.0|1.0] ""  EMS,IBOX
 SG_ CF_Fatc_ChkSum : 56|8@1+ (1.0,0.0) [0.0|255.0] ""  EMS,IBOX,SPAS

BO_ 902 WHL_SPD11: 8 ABS
 SG_ WHL_SPD_FL : 0|14@1+ (0.03125,0.0) [0.0|511.96875] "km/h"  _4WD,AFLS,AHLS,AVM,CLU,CUBIS,ECS,EMS,EPB,IBOX,LDWS_LKAS,PGS,PSB,SCC,SMK,SPAS,TCU,TPMS,_4WD,ACU,AFLS,AHLS,AVM,CLU,ECS,EMS,EPB,IBOX,LCA,LDWS_LKAS,PGS,PSB,SCC,SMK,SPAS,TCU,TPMS
 SG_ WHL_SPD_FR : 16|14@1+ (0.03125,0.0) [0.0|511.96875] "km/h"  _4WD,ACU,AFLS,AHLS,AVM,CLU,CUBIS,ECS,EMS,EPB,IBOX,LDWS_LKAS,PGS,PSB,SCC,SMK,SPAS,TCU,TPMS,_4WD,ACU,AFLS,AHLS,AVM,CLU,ECS,EMS,EPB,IBOX,LCA,LDWS_LKAS,PGS,PSB,SCC,SMK,SPAS,TCU,TPMS
 SG_ WHL_SPD_RL : 32|14@1+ (0.03125,0.0) [0.0|511.96875] "km/h"  _4WD,AFLS,AHLS,AVM,BCM,CLU,CUBIS,ECS,EMS,EPB,IBOX,LDWS_LKAS,PGS,PSB,SCC,SMK,SPAS,TCU,TPMS,_4WD,ACU,AFLS,AHLS,AVM,BCM,CLU,ECS,EMS,EPB,IBOX,LCA,LDWS_LKAS,PGS,PSB,SCC,SMK,SPAS,TCU,TPMS
 SG_ WHL_SPD_RR : 48|14@1+ (0.03125,0.0) [0.0|511.96875] "km/h"  _4WD,AFLS,AHLS,AVM,CLU,CUBIS,ECS,EMS,EPB,IBOX,LDWS_LKAS,PGS,PSB,SCC,SMK,SPAS,TCU,TPMS,_4WD,ACU,AFLS,AHLS,AVM,CLU,ECS,EMS,EPB,IBOX,LCA,LDWS_LKAS,PGS,PSB,SCC,SMK,SPAS,TCU,TPMS
 SG_ WHL_SPD_AliveCounter_LSB : 14|2@1+ (1.0,0.0) [0.0|15.0] ""  _4WD,EMS,LPI,TCU,TMU
 SG_ WHL_SPD_AliveCounter_MSB : 30|2@1+ (1.0,0.0) [0.0|15.0] ""  _4WD,EMS,LPI,TCU,TMU
 SG_ WHL_SPD_Checksum_LSB : 46|2@1+ (1.0,0.0) [0.0|15.0] ""  _4WD,EMS,LPI,TCU,TMU
 SG_ WHL_SPD_Checksum_MSB : 62|2@1+ (1.0,0.0) [0.0|15.0] ""  _4WD,EMS,LPI,TCU,TMU

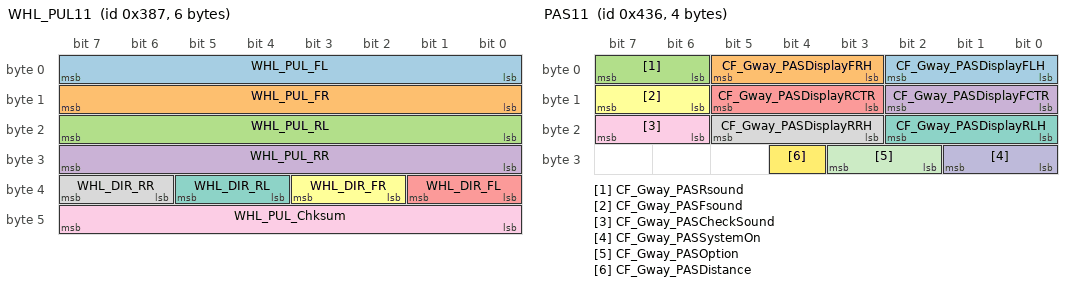
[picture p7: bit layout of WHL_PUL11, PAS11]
BO_ 903 WHL_PUL11: 6 ABS
 SG_ WHL_PUL_FL : 0|8@1+ (0.5,0.0) [0.0|127.5] "pulse count"  CUBIS,EPB,IBOX,SPAS,TMU,TPMS,CUBIS,EPB,IBOX,LDWS_LKAS,SPAS,TMU,TPMS
 SG_ WHL_PUL_FR : 8|8@1+ (0.5,0.0) [0.0|127.5] "pulse count"  CUBIS,EPB,IBOX,SPAS,TMU,TPMS,CUBIS,EPB,IBOX,LDWS_LKAS,SPAS,TMU,TPMS
 SG_ WHL_PUL_RL : 16|8@1+ (0.5,0.0) [0.0|127.5] "pulse count"  CUBIS,EPB,IBOX,SPAS,TMU,TPMS,CUBIS,EPB,IBOX,LDWS_LKAS,SPAS,TMU,TPMS
 SG_ WHL_PUL_RR : 24|8@1+ (0.5,0.0) [0.0|127.5] "pulse count"  CUBIS,EPB,IBOX,SPAS,TMU,TPMS,CUBIS,EPB,IBOX,LDWS_LKAS,SPAS,TMU,TPMS
 SG_ WHL_DIR_FL : 32|2@1+ (1.0,0.0) [0.0|3.0] ""  EPB,SPAS,TPMS,EPB,LCA,SPAS,TPMS
 SG_ WHL_DIR_FR : 34|2@1+ (1.0,0.0) [0.0|3.0] ""  EPB,SPAS,TPMS,EPB,LCA,SPAS,TPMS
 SG_ WHL_DIR_RL : 36|2@1+ (1.0,0.0) [0.0|3.0] ""  EPB,SPAS,TPMS,EPB,LCA,SPAS,TPMS
 SG_ WHL_DIR_RR : 38|2@1+ (1.0,0.0) [0.0|3.0] ""  EPB,SPAS,TPMS,EPB,LCA,SPAS,TPMS
 SG_ WHL_PUL_Chksum : 40|8@1+ (1.0,0.0) [0.0|255.0] ""  EPB,SPAS,TPMS,EPB,LCA,LDWS_LKAS,SPAS,TPMS

BO_ 909 FCA11: 8 FCA
 SG_ CF_VSM_Prefill : 0|1@1+ (1,0) [0|1] "" ESC
 SG_ CF_VSM_HBACmd : 1|2@1+ (1,0) [0|3] "" ESC
 SG_ CF_VSM_Warn : 3|2@1+ (1,0) [0|3] "" ACU,CLU,ESC
 SG_ CF_VSM_BeltCmd : 5|3@1+ (1,0) [0|7] "" ESC
 SG_ CR_VSM_DecCmd : 8|8@1+ (0.01,0) [0|2.55] "g" ESC
 SG_ FCA_Status : 18|2@1+ (1,0) [0|3] "" ACU,CLU,ESC
 SG_ FCA_CmdAct : 20|1@1+ (1,0) [0|1] "" ESC
 SG_ FCA_StopReq : 21|1@1+ (1,0) [0|1] "" CLU,ESC
 SG_ FCA_DrvSetStatus : 22|3@1+ (1,0) [0|7] "" CLU,ESC
 SG_ CF_VSM_DecCmdAct : 31|1@1+ (1,0) [0|1] "" ESC
 SG_ FCA_Failinfo : 32|3@1+ (1,0) [0|7] "" ACU,CLU,ESC
 SG_ FCA_RelativeVelocity : 39|9@1+ (0.1,-25.5) [-25.5|25.5] "m/s" iBAU
 SG_ FCA_TimetoCollision : 48|8@1+ (10,0) [0|2540] "ms" iBAU
 SG_ CR_FCA_Alive : 56|4@1+ (1,0) [0|15] "" ESC
 SG_ CR_FCA_ChkSum : 60|4@1+ (1,0) [0|15] "" ESC
 SG_ Supplemental_Counter : 35|4@1+ (1,0) [0|15] "" XXX
 SG_ PAINT1_Status : 16|2@1+ (1,0) [0|1] "" XXX

BO_ 913 BCM_PO_11: 8 Vector__XXX
 SG_ BCM_Door_Dri_Status : 5|1@0+ (1,0) [0|1] "" PT_ESC_ABS
 SG_ BCM_Shift_R_MT_SW_Status : 39|2@0+ (1,0) [0|3] "" PT_ESC_ABS

BO_ 916 TCS13: 8 ESC
 SG_ aBasis : 0|11@1+ (0.01,-10.23) [-10.23|10.24] "m/s^2"  EMS,SCC
 SG_ BrakeLight : 11|1@1+ (1.0,0.0) [0.0|1.0] ""  CLU,EMS,SCC
 SG_ DCEnable : 12|1@1+ (1.0,0.0) [0.0|1.0] ""  EMS,SCC
 SG_ AliveCounterTCS : 13|3@1+ (1.0,0.0) [0.0|7.0] ""  EMS,SCC
 SG_ Pre_TCS_CTL : 16|1@1+ (1.0,0.0) [0.0|1.0] ""  Vector__XXX
 SG_ EBA_ACK : 17|1@1+ (1.0,0.0) [0.0|1.0] ""  Vector__XXX
 SG_ FCA_ACK : 18|1@1+ (1.0,0.0) [0.0|1.0] ""  Vector__XXX
 SG_ DF_BF_STAT : 19|2@1+ (1.0,0.0) [0.0|3.0] ""  BCW
 SG_ SCCReqLim : 21|2@1+ (1.0,0.0) [0.0|3.0] ""  SCC
 SG_ TQI_SCC : 23|9@1+ (0.390625,0.0) [0.0|199.609375] "%"  Vector__XXX
 SG_ ACCEL_REF_ACC : 32|11@1+ (0.01,-10.23) [-10.23|10.24] "m/s^2"  EMS,SCC
 SG_ ACCEnable : 43|2@1+ (1.0,0.0) [0.0|3.0] ""  EMS,SCC
 SG_ DriverOverride : 45|2@1+ (1.0,0.0) [0.0|3.0] ""  EMS,SCC
 SG_ StandStill : 47|1@1+ (1.0,0.0) [0.0|1.0] ""  EMS,SCC
 SG_ CheckSum_TCS3 : 48|4@1+ (1.0,0.0) [0.0|15.0] ""  EMS,SCC
 SG_ ACC_EQUIP : 52|1@1+ (1.0,0.0) [0.0|1.0] ""  EMS,SCC
 SG_ PBRAKE_ACT : 53|1@1+ (1.0,0.0) [0.0|1.0] ""  EMS,SCC
 SG_ ACC_REQ : 54|1@1+ (1.0,0.0) [0.0|1.0] ""  EMS
 SG_ DriverBraking : 55|1@1+ (1.0,0.0) [0.0|1.0] ""  EMS,SCC
 SG_ CF_VSM_Coded : 56|1@1+ (1.0,0.0) [0.0|1.0] ""  SCC
 SG_ CF_VSM_Avail : 57|2@1+ (1.0,0.0) [0.0|3.0] ""  CLU,SCC
 SG_ CF_VSM_Handshake : 59|1@1+ (1.0,0.0) [0.0|1.0] ""  SCC
 SG_ CF_DriBkeStat : 60|1@1+ (1.0,0.0) [0.0|1.0] ""  SCC
 SG_ CF_VSM_ConfSwi : 61|2@1+ (1.0,0.0) [0.0|3.0] ""  SCC
 SG_ AEB_EQUIP : 63|1@1+ (1.0,0.0) [0.0|1.0] ""  SCC

BO_ 1008 ???: 8 ???

BO_ 1015 ???: 8 ???

BO_ 1040 CGW_USM1: 8 BCM
 SG_ CF_Gway_ATTurnRValue : 0|2@1+ (1.0,0.0) [0.0|3.0] ""  CLU
 SG_ CF_Gway_PTGMRValue : 2|2@1+ (1.0,0.0) [0.0|3.0] ""  CLU
 SG_ CF_Gway_EscortHLRValue : 4|2@1+ (1.0,0.0) [0.0|3.0] ""  CLU
 SG_ CF_Gway_TTUnlockRValue : 6|2@1+ (1.0,0.0) [0.0|3.0] ""  CLU
 SG_ CF_Gway_ADrLRValue : 8|3@1+ (1.0,0.0) [0.0|7.0] ""  CLU
 SG_ CF_Gway_ADrURValue : 11|3@1+ (1.0,0.0) [0.0|7.0] ""  CLU
 SG_ CF_Gway_SCMRValue : 14|2@1+ (1.0,0.0) [0.0|3.0] ""  CLU
 SG_ CF_Gway_WlightRValue : 16|2@1+ (1.0,0.0) [0.0|3.0] ""  CLU
 SG_ CF_Gway_PSMRValue : 18|3@1+ (1.0,0.0) [0.0|7.0] ""  CLU
 SG_ CF_Gway_OTTurnRValue : 21|3@1+ (1.0,0.0) [0.0|7.0] ""  CLU
 SG_ CF_Gway_DrLockSoundRValue : 24|3@1+ (1.0,0.0) [0.0|7.0] ""  CLU
 SG_ CF_Gway_HAnBRValue : 27|3@1+ (1.0,0.0) [0.0|7.0] ""  CLU
 SG_ CF_Gway_MoodLpRValue : 30|2@1+ (1.0,0.0) [0.0|3.0] ""  CLU
 SG_ CF_Gway_HfreeTrunkRValue : 32|3@1+ (1.0,0.0) [0.0|7.0] ""  CLU
 SG_ CF_Gway_AutoLightRValue : 35|3@1+ (1.0,0.0) [0.0|7.0] ""  CLU
 SG_ CF_Gway_RearWiperRValue : 38|2@1+ (1.0,0.0) [0.0|3.0] ""  CLU
 SG_ CF_Gway_PasSpkrLvRValue : 40|3@1+ (1.0,0.0) [0.0|7.0] ""  CLU

BO_ 1067 ???: 8 ???

BO_ 1078 PAS11: 4 BCM
 SG_ CF_Gway_PASDisplayFLH : 0|3@1+ (1.0,0.0) [0.0|7.0] ""  AVM,CLU,AVM
 SG_ CF_Gway_PASDisplayFRH : 3|3@1+ (1.0,0.0) [0.0|7.0] ""  AVM,CLU,AVM
 SG_ CF_Gway_PASRsound : 6|2@1+ (1.0,0.0) [0.0|3.0] ""  CLU,Dummy
 SG_ CF_Gway_PASDisplayFCTR : 8|3@1+ (1.0,0.0) [0.0|7.0] ""  AVM,CLU,AVM
 SG_ CF_Gway_PASDisplayRCTR : 11|3@1+ (1.0,0.0) [0.0|7.0] ""  AVM,CLU,PGS,AVM
 SG_ CF_Gway_PASFsound : 14|2@1+ (1.0,0.0) [0.0|3.0] ""  CLU,Dummy
 SG_ CF_Gway_PASDisplayRLH : 16|3@1+ (1.0,0.0) [0.0|7.0] ""  AVM,CLU,PGS,AVM
 SG_ CF_Gway_PASDisplayRRH : 19|3@1+ (1.0,0.0) [0.0|7.0] ""  AVM,CLU,PGS,AVM
 SG_ CF_Gway_PASCheckSound : 22|2@1+ (1.0,0.0) [0.0|3.0] ""  CLU,Dummy
 SG_ CF_Gway_PASSystemOn : 24|2@1+ (1.0,0.0) [0.0|3.0] ""  CLU,Dummy
 SG_ CF_Gway_PASOption : 26|2@1+ (1.0,0.0) [0.0|3.0] ""  CLU
 SG_ CF_Gway_PASDistance : 28|1@1+ (1.0,0.0) [0.0|1.0] ""  CLU

BO_ 1155 FCA12: 8 FCA
 SG_ FCA_USM : 0|3@1+ (1,0) [0|7] "" CGW,CLU,ESC
 SG_ FCA_DrvSetState : 3|3@1+ (1,0) [0|7] "" CGW

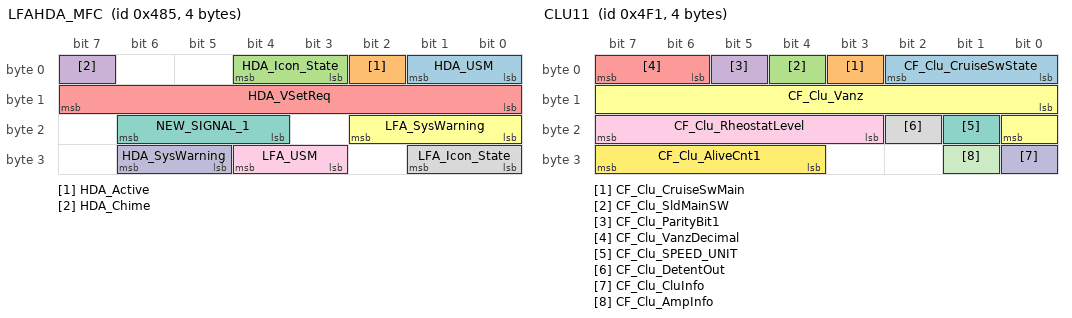
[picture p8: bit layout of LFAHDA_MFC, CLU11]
BO_ 1157 LFAHDA_MFC: 4 XXX
 SG_ HDA_USM : 0|2@1+ (1,0) [0|3] "" XXX
 SG_ HDA_Active : 2|1@1+ (1,0) [0|1] "" XXX
 SG_ HDA_Icon_State : 3|2@1+ (1,0) [0|3] "" XXX
 SG_ HDA_Chime : 7|1@1+ (1,0) [0|1] "" XXX
 SG_ HDA_VSetReq : 8|8@1+ (1,0) [0|255] "km/h" XXX
 SG_ LFA_SysWarning : 16|3@1+ (1,0) [0|7] "" XXX
 SG_ NEW_SIGNAL_1 : 20|3@1+ (1,0) [0|7] "" XXX
 SG_ LFA_Icon_State : 24|2@1+ (1,0) [0|3] "" XXX
 SG_ LFA_USM : 27|2@1+ (1,0) [0|3] "" XXX
 SG_ HDA_SysWarning : 29|2@1+ (1,0) [0|3] "" XXX

BO_ 1170 EMS19: 8 EMS
 SG_ CF_Ems_BrkReq : 0|1@1+ (1.0,0.0) [0.0|1.0] ""  ESC,IBOX,TCU
 SG_ CF_Ems_DnShftReq : 1|4@1+ (1.0,0.0) [0.0|14.0] ""  IBOX,TCU
 SG_ CF_Ems_RepModChk : 5|2@1+ (1.0,0.0) [0.0|3.0] ""  IBOX
 SG_ CF_Ems_AAFOpenReq : 7|1@1+ (1.0,0.0) [0.0|1.0] ""  AAF,IBOX
 SG_ CF_Ems_DecelReq : 8|12@1+ (0.0010,-4.094) [-4.094|0.0] "m/s^2"  ESC,IBOX,TCU
 SG_ CR_Ems_BstPre : 20|12@1+ (1.322,0.0) [0.0|4094.0] "hPa"  CLU,IBOX
 SG_ CR_Ems_EngOilTemp : 32|8@1+ (0.75,-40.0) [0.0|254.0] "deg"  CLU,IBOX
 SG_ CR_CLU_Gear_Ind : 41|4@0+ (1.0,0.0) [0.0|7.0] ""  CLU
 SG_ CF_Ems_ModeledAmbTemp : 48|8@1+ (0.5,-41.0) [-41.0|85.5] "deg"  AAF,IBOX
 SG_ CF_Ems_OPSFail : 56|1@1+ (1.0,0.0) [0.0|1.0] ""  CLU,IBOX
 SG_ CF_Ems_AliveCounterEMS9 : 58|2@1+ (1.0,0.0) [0.0|3.0] ""  AAF,ABS,CUBIS,ECS,EPB,IBOX,MDPS,REA,SCC,SMK,TCU
 SG_ CF_Ems_ChecksumEMS9 : 60|4@1+ (1.0,0.0) [0.0|15.0] ""  AAF,ABS,CUBIS,ECS,EPB,IBOX,MDPS,REA,SCC,SMK,TCU

BO_ 1181 ???: 5 ???

BO_ 1184 ???: 8 ???
 SG_ Current_Suspension_Mode : 0|2@1+ (1.0,0.0) [0.0|3.0] ""  ???
 SG_ Current_Steering_Mode : 2|2@1+ (1.0,0.0) [0.0|3.0] ""  ???
 SG_ Current_Auto_Rev_Mode : 4|2@1+ (1.0,0.0) [0.0|3.0] ""  ???
 SG_ Current_Engine_Mode : 6|2@1+ (1.0,0.0) [0.0|3.0] ""  ???
 SG_ Current_LSD_Mode : 8|2@1+ (1.0,0.0) [0.0|3.0] ""  ???
 SG_ Current_Transmission_Mode : 10|2@1+ (1.0,0.0) [0.0|3.0] ""  ???
 SG_ Current_Exhaust_Mode : 12|2@1+ (1.0,0.0) [0.0|3.0] ""  ???
 SG_ Current_ESC_Mode : 14|2@1+ (1.0,0.0) [0.0|3.0] ""  ???
 SG_ N_Custom_Steering_Mode : 16|2@1+ (1.0,0.0) [0.0|3.0] ""  ???
 SG_ N_Custom_Engine_Mode : 18|2@1+ (1.0,0.0) [0.0|3.0] ""  ???
 SG_ Current_Drive_Mode : 20|4@1+ (1.0,0.0) [0.0|15.0] ""  ???
 SG_ N_Custom_LSD_Mode : 24|2@1+ (1.0,0.0) [0.0|3.0] ""  ???
 SG_ N_Custom_Transmission_Mode : 26|2@1+ (1.0,0.0) [0.0|3.0] ""  ???
 SG_ N_Custom_Exhaust_Mode : 28|2@1+ (1.0,0.0) [0.0|3.0] ""  ???
 SG_ N_Custom_Suspension_Mode : 30|2@1+ (1.0,0.0) [0.0|3.0] ""  ???
 SG_ N_Custom_ESC_Mode : 48|2@1+ (1.0,0.0) [0.0|3.0] ""  ???
 SG_ N_Custom_Auto_Rev_Mode : 50|2@1+ (1.0,0.0) [0.0|3.0] ""  ???

BO_ 1191 MFC_4a7: 8 XXX
 SG_ PAINT1 : 0|1@0+ (1,0) [0|1] "" XXX

BO_ 1193 ???: 8 ???

BO_ 1253 ???: 8 ???

BO_ 1254 ???: 8 ???

BO_ 1255 ???: 8 ???

BO_ 1265 CLU11: 4 CLU
 SG_ CF_Clu_CruiseSwState : 0|3@1+ (1.0,0.0) [0.0|7.0] ""  EMS,LDWS_LKAS,SCC
 SG_ CF_Clu_CruiseSwMain : 3|1@1+ (1.0,0.0) [0.0|1.0] ""  EMS,LDWS_LKAS,SCC
 SG_ CF_Clu_SldMainSW : 4|1@1+ (1.0,0.0) [0.0|1.0] ""  EMS
 SG_ CF_Clu_ParityBit1 : 5|1@1+ (1.0,0.0) [0.0|1.0] "pulse count"  EMS
 SG_ CF_Clu_VanzDecimal : 6|2@1+ (0.125,0.0) [0.0|0.375] ""  EMS
 SG_ CF_Clu_Vanz : 8|9@1+ (0.5,0.0) [0.0|255.5] "km/h or MPH"  BCM,CUBIS,EMS,IBOX,LDWS_LKAS,MDPS,SCC
 SG_ CF_Clu_SPEED_UNIT : 17|1@1+ (1.0,0.0) [0.0|1.0] ""  BCM,CUBIS,EMS,IBOX,LDWS_LKAS,MDPS,SCC
 SG_ CF_Clu_DetentOut : 18|1@1+ (1.0,0.0) [0.0|1.0] ""  AVM,BCM,LCA,PGS,SPAS
 SG_ CF_Clu_RheostatLevel : 19|5@1+ (1.0,0.0) [0.0|31.0] ""  AVM,BCM,LCA,PGS,SPAS
 SG_ CF_Clu_CluInfo : 24|1@1+ (1.0,0.0) [0.0|1.0] ""  BCM
 SG_ CF_Clu_AmpInfo : 25|1@1+ (1.0,0.0) [0.0|1.0] ""  BCM
 SG_ CF_Clu_AliveCnt1 : 28|4@1+ (1.0,0.0) [0.0|15.0] ""  AHLS,EMS,EPB,LDWS_LKAS,MDPS,SCC

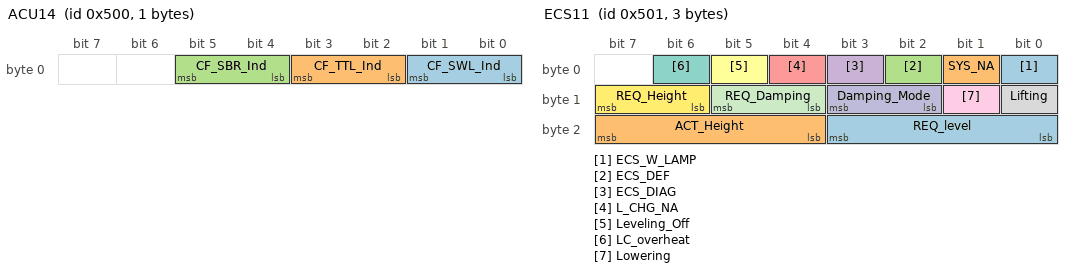
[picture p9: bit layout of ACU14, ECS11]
BO_ 1280 ACU14: 1 ACU
 SG_ CF_SWL_Ind : 0|2@1+ (1.0,0.0) [0.0|3.0] ""  CLU
 SG_ CF_TTL_Ind : 2|2@1+ (1.0,0.0) [0.0|3.0] ""  CLU
 SG_ CF_SBR_Ind : 4|2@1+ (1.0,0.0) [0.0|3.0] ""  BCM,CLU

BO_ 1281 ECS11: 3 ECS
 SG_ ECS_W_LAMP : 0|1@1+ (1.0,0.0) [0.0|1.0] ""  CLU,CUBIS,IBOX
 SG_ SYS_NA : 1|1@1+ (1.0,0.0) [0.0|1.0] ""  CLU
 SG_ ECS_DEF : 2|1@1+ (1.0,0.0) [0.0|1.0] ""  CLU
 SG_ ECS_DIAG : 3|1@1+ (1.0,0.0) [0.0|1.0] ""  CLU
 SG_ L_CHG_NA : 4|1@1+ (1.0,0.0) [0.0|1.0] ""  CLU
 SG_ Leveling_Off : 5|1@1+ (1.0,0.0) [0.0|1.0] ""  CLU
 SG_ LC_overheat : 6|1@1+ (1.0,0.0) [0.0|1.0] ""  CLU
 SG_ Lifting : 8|1@1+ (1.0,0.0) [0.0|1.0] ""  CLU
 SG_ Lowering : 9|1@1+ (1.0,0.0) [0.0|1.0] ""  CLU
 SG_ Damping_Mode : 10|2@1+ (1.0,0.0) [0.0|3.0] ""  CLU
 SG_ REQ_Damping : 12|2@1+ (1.0,0.0) [0.0|3.0] ""  CLU
 SG_ REQ_Height : 14|2@1+ (1.0,0.0) [0.0|3.0] ""  CLU
 SG_ REQ_level : 16|4@1+ (1.0,0.0) [0.0|15.0] ""  CLU
 SG_ ACT_Height : 20|4@1+ (1.0,0.0) [0.0|15.0] ""  CLU

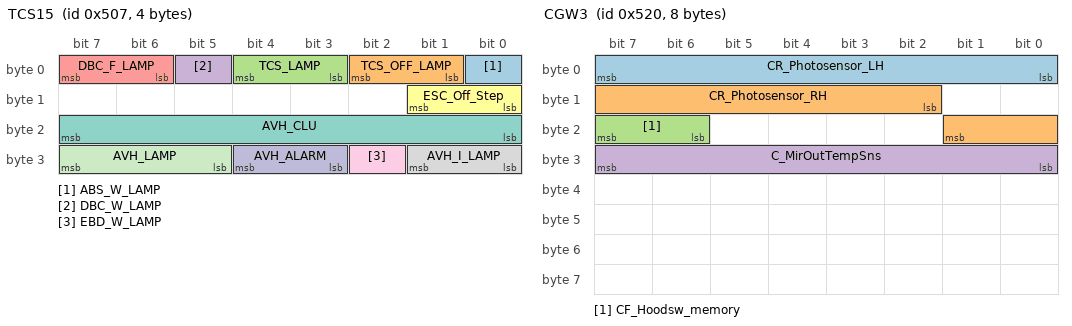
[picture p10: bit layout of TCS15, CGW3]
BO_ 1287 TCS15: 4 ESC
 SG_ ABS_W_LAMP : 0|1@1+ (1.0,0.0) [0.0|1.0] ""  _4WD,CLU,CUBIS,IBOX
 SG_ TCS_OFF_LAMP : 1|2@1+ (1.0,0.0) [0.0|1.0] ""  _4WD,ACU,CLU
 SG_ TCS_LAMP : 3|2@1+ (1.0,0.0) [0.0|3.0] ""  _4WD,ACU,CLU,CUBIS,IBOX,SCC
 SG_ DBC_W_LAMP : 5|1@1+ (1.0,0.0) [0.0|1.0] ""  _4WD,CLU
 SG_ DBC_F_LAMP : 6|2@1+ (1.0,0.0) [0.0|3.0] ""  _4WD,CLU
 SG_ ESC_Off_Step : 8|2@1+ (1.0,0.0) [0.0|3.0] ""  CLU
 SG_ AVH_CLU : 16|8@1+ (1.0,0.0) [0.0|255.0] ""  CLU,EPB
 SG_ AVH_I_LAMP : 24|2@1+ (1.0,0.0) [0.0|3.0] ""  EPB
 SG_ EBD_W_LAMP : 26|1@1+ (1.0,0.0) [0.0|1.0] ""  _4WD,CLU
 SG_ AVH_ALARM : 27|2@1+ (1.0,0.0) [0.0|3.0] ""  CLU
 SG_ AVH_LAMP : 29|3@1+ (1.0,0.0) [0.0|7.0] ""  CLU,EPB,SPAS

BO_ 1292 CLU13: 8 CLU
 SG_ CF_Clu_LowfuelWarn : 0|2@1+ (1.0,0.0) [0.0|3.0] ""  BCM,FPCM,IBOX
 SG_ CF_Clu_RefDetMod : 2|1@1+ (1.0,0.0) [0.0|1.0] ""  IBOX
 SG_ CF_Clu_AvgFCU : 3|2@1+ (1.0,0.0) [0.0|3.0] ""  IBOX
 SG_ CF_Clu_AvsmCur : 5|1@1+ (1.0,0.0) [0.0|1.0] ""  ESC,SCC
 SG_ CF_Clu_AvgFCI : 6|10@1+ (0.1,0.0) [0.0|102.2] ""  IBOX
 SG_ CF_Clu_DrivingModeSwi : 16|2@1+ (1.0,0.0) [0.0|3.0] ""  DATC,ECS,EMS,ESC,IAP,MDPS,TCU
 SG_ CF_Clu_DrivingMode_Without_N_Mode : 20|4@0+ (1.0,0.0) [0.0|15.0] "" ???
 SG_ CF_Clu_FlexSteerSW : 23|1@1+ (1.0,0.0) [0.0|1.0] ""  MDPS
 SG_ CF_Clu_DTE : 24|10@1+ (1.0,0.0) [0.0|1023.0] ""  DATC
 SG_ CF_Clu_TripUnit : 34|2@1+ (1.0,0.0) [0.0|3.0] ""  DATC
 SG_ CF_Clu_SWL_Stat : 36|3@1+ (1.0,0.0) [0.0|7.0] ""  ACU,EMS
 SG_ CF_Clu_ActiveEcoSW : 39|1@1+ (1.0,0.0) [0.0|1.0] ""  DATC,EMS,TCU
 SG_ CF_Clu_DrivingMode_With_N_Mode : 40|4@1+ (1.0,0.0) [0.0|15.0] ""  ???
 SG_ CF_Clu_IsaMainSW : 43|1@1+ (1.0,0.0) [0.0|1.0] ""  EMS
 SG_ CF_Clu_LdwsLkasSW : 56|1@1+ (1.0,0.0) [0.0|1.0] ""  LDWS_LKAS
 SG_ CF_Clu_AltLStatus : 59|1@1+ (1.0,0.0) [0.0|1.0] ""  BCM,DATC,EMS
 SG_ CF_Clu_AliveCnt2 : 60|4@1+ (1.0,0.0) [0.0|15.0] ""  EMS,LDWS_LKAS

BO_ 1294 ???: 8 ???
 SG_ Clutch_OnOff_Swi : 2|2@1+ (1.0,0.0) [0.0|3.0] ""  ???

BO_ 1312 CGW3: 8 BCM
 SG_ CR_Photosensor_LH : 0|8@1+ (78.125,0.0) [0.0|20000.0] ""  DATC,DATC
 SG_ CR_Photosensor_RH : 10|8@1+ (78.125,0.0) [0.0|20000.0] ""  DATC,DATC
 SG_ CF_Hoodsw_memory : 22|2@1+ (1.0,0.0) [0.0|3.0] ""  EMS,EMS
 SG_ C_MirOutTempSns : 24|8@1+ (0.5,-40.5) [-40.0|60.0] "deg"  AAF,CLU,DATC,EMS,SPAS,AAF,DATC,EMS,SPAS

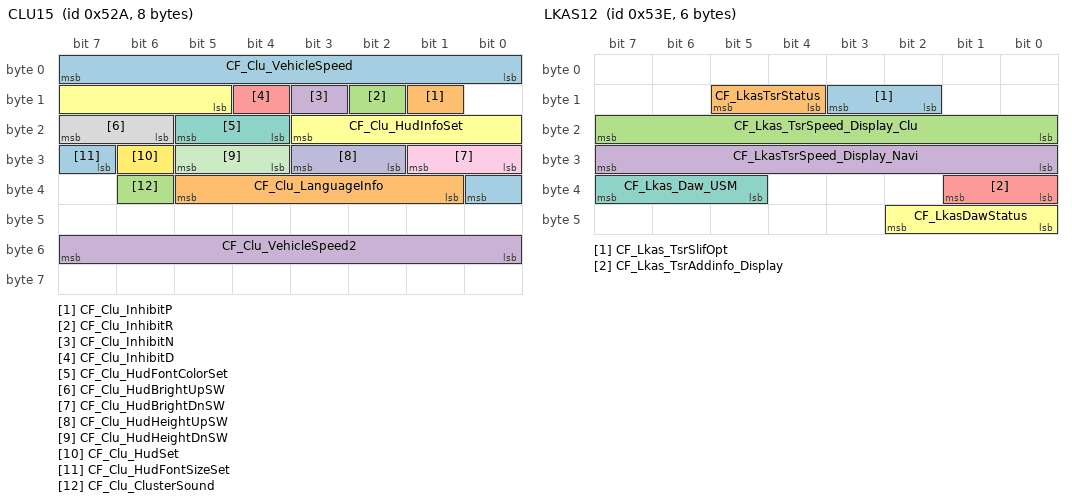
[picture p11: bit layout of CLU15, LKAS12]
BO_ 1322 CLU15: 8 CLU
 SG_ CF_Clu_VehicleSpeed : 0|8@1+ (1.0,0.0) [0.0|255.0] ""  BCM
 SG_ CF_Clu_InhibitP : 9|1@1+ (1.0,0.0) [0.0|1.0] ""  BCM
 SG_ CF_Clu_InhibitR : 10|1@1+ (1.0,0.0) [0.0|1.0] ""  BCM
 SG_ CF_Clu_InhibitN : 11|1@1+ (1.0,0.0) [0.0|1.0] ""  BCM
 SG_ CF_Clu_InhibitD : 12|1@1+ (1.0,0.0) [0.0|1.0] ""  BCM
 SG_ CF_Clu_HudInfoSet : 13|7@1+ (1.0,0.0) [0.0|127.0] ""  HUD
 SG_ CF_Clu_HudFontColorSet : 20|2@1+ (1.0,0.0) [0.0|3.0] ""  HUD
 SG_ CF_Clu_HudBrightUpSW : 22|2@1+ (1.0,0.0) [0.0|3.0] ""  HUD
 SG_ CF_Clu_HudBrightDnSW : 24|2@1+ (1.0,0.0) [0.0|3.0] ""  HUD
 SG_ CF_Clu_HudHeightUpSW : 26|2@1+ (1.0,0.0) [0.0|3.0] ""  HUD
 SG_ CF_Clu_HudHeightDnSW : 28|2@1+ (1.0,0.0) [0.0|3.0] ""  HUD
 SG_ CF_Clu_HudSet : 30|1@1+ (1.0,0.0) [0.0|1.0] ""  HUD
 SG_ CF_Clu_HudFontSizeSet : 31|2@1+ (1.0,0.0) [0.0|3.0] ""  HUD
 SG_ CF_Clu_LanguageInfo : 33|5@1+ (1.0,0.0) [0.0|31.0] ""  BCM,PGS
 SG_ CF_Clu_ClusterSound : 38|1@1- (1.0,0.0) [0.0|0.0] ""  BCM,CGW,FATC
 SG_ CF_Clu_VehicleSpeed2 : 48|8@1+ (1,0) [0|255] "" XXX

BO_ 1342 LKAS12: 6 LDWS_LKAS
 SG_ CF_Lkas_TsrSlifOpt : 10|2@1+ (1.0,0.0) [0.0|3.0] ""  CLU
 SG_ CF_LkasTsrStatus : 12|2@1+ (1.0,0.0) [0.0|3.0] ""  CLU
 SG_ CF_Lkas_TsrSpeed_Display_Clu : 16|8@1+ (1.0,0.0) [0.0|255.0] ""  CLU
 SG_ CF_LkasTsrSpeed_Display_Navi : 24|8@1+ (1.0,0.0) [0.0|255.0] ""  BCM,CLU
 SG_ CF_Lkas_TsrAddinfo_Display : 32|2@1+ (1.0,0.0) [0.0|3.0] ""  CLU
 SG_ CF_LkasDawStatus : 40|3@1+ (1,0) [0|7] "" CLU
 SG_ CF_Lkas_Daw_USM : 37|3@1+ (1,0) [0|7] "" CLU

BO_ 1345 CGW1: 8 BCM
 SG_ CF_Gway_IGNSw : 0|3@1+ (1.0,0.0) [0.0|7.0] ""  AVM,CLU,ECS,EMS,EPB,ESC,IBOX,LVR,MDPS,SAS,SCC,ECS,EMS,EPB,ESC,IBOX,LVR,MDPS,SAS,SCC
 SG_ CF_Gway_RKECmd : 3|3@1+ (1.0,0.0) [0.0|7.0] ""  CLU,ECS,EMS,IBOX,ECS,EMS,IBOX
 SG_ CF_Gway_DrvKeyLockSw : 6|1@1+ (1.0,0.0) [0.0|1.0] ""  ECS,EMS,IBOX,ECS,EMS,IBOX
 SG_ CF_Gway_DrvKeyUnlockSw : 7|1@1+ (1.0,0.0) [0.0|1.0] ""  ECS,EMS,IBOX,ECS,EMS,IBOX
 SG_ CF_Gway_DrvDrSw : 8|2@1+ (1.0,0.0) [0.0|3.0] ""  CLU,ECS,EMS,EPB,ESC,IBOX,SCC,TCU,ECS,EMS,EPB,ESC,IBOX,SCC,TCU
 SG_ CF_Gway_DrvSeatBeltSw : 10|2@1+ (1.0,0.0) [0.0|3.0] ""  EMS,EPB,ESC,IBOX,PSB,TCU,EMS,EPB,ESC,IBOX,PSB,TCU
 SG_ CF_Gway_TrunkTgSw : 12|2@1+ (1.0,0.0) [0.0|3.0] ""  CLU,ECS,EMS,EPB,ESC,IBOX,ECS,EMS,EPB,ESC,IBOX
 SG_ CF_Gway_AstSeatBeltSw : 14|2@1+ (1.0,0.0) [0.0|3.0] ""  IBOX,PSB,IBOX,PSB
 SG_ CF_Gway_SMKOption : 16|1@1+ (1.0,0.0) [0.0|1.0] ""  CLU,EMS,IBOX,EMS,IBOX,SMK
 SG_ CF_Gway_HoodSw : 17|2@1+ (1.0,0.0) [0.0|3.0] ""  CLU,EMS,EPB,ESC,IBOX,EMS,EPB,ESC,IBOX
 SG_ CF_Gway_TurnSigLh : 19|2@1+ (1.0,0.0) [0.0|3.0] ""  CLU,EMS,IBOX,LCA,LDWS_LKAS,SCC,EMS,IBOX,LCA,LDWS_LKAS,SCC
 SG_ CF_Gway_WiperIntT : 21|3@1+ (1.0,0.0) [0.0|7.0] ""  CLU,EMS,IBOX,LDWS_LKAS,EMS,ESC,IBOX,LDWS_LKAS
 SG_ CF_Gway_WiperIntSw : 24|1@1+ (1.0,0.0) [0.0|1.0] ""  CLU,EMS,IBOX,LDWS_LKAS,EMS,ESC,IBOX,LDWS_LKAS
 SG_ CF_Gway_WiperLowSw : 25|1@1+ (1.0,0.0) [0.0|1.0] ""  CLU,EMS,IBOX,LDWS_LKAS,EMS,ESC,IBOX,LDWS_LKAS
 SG_ CF_Gway_WiperHighSw : 26|1@1+ (1.0,0.0) [0.0|1.0] ""  CLU,EMS,IBOX,LDWS_LKAS,EMS,ESC,IBOX,LDWS_LKAS
 SG_ CF_Gway_WiperAutoSw : 27|1@1+ (1.0,0.0) [0.0|1.0] ""  CLU,EMS,IBOX,LDWS_LKAS,EMS,ESC,IBOX,LDWS_LKAS
 SG_ CF_Gway_RainSnsState : 28|3@1+ (1.0,0.0) [0.0|7.0] ""  AFLS,EMS,IBOX,LDWS_LKAS,AFLS,EMS,ESC,IBOX,LDWS_LKAS
 SG_ CF_Gway_HeadLampLow : 31|1@1+ (1.0,0.0) [0.0|1.0] ""  AFLS,CLU,EMS,IBOX,LDWS_LKAS,SNV,AFLS,EMS,IBOX,LDWS_LKAS,SNV
 SG_ CF_Gway_HeadLampHigh : 32|1@1+ (1.0,0.0) [0.0|1.0] ""  AFLS,CLU,EMS,IBOX,LDWS_LKAS,AFLS,EMS,IBOX,LDWS_LKAS
 SG_ CF_Gway_HazardSw : 33|2@1+ (1.0,0.0) [0.0|3.0] ""  ABS,EMS,ESC,IBOX,LCA,LDWS_LKAS,ABS,EMS,ESC,IBOX,LCA,LDWS_LKAS
 SG_ CF_Gway_AstDrSw : 35|1@1+ (1.0,0.0) [0.0|1.0] ""  CLU,IBOX,IBOX
 SG_ CF_Gway_DefoggerRly : 36|1@1+ (1.0,0.0) [0.0|1.0] ""  EMS,IBOX,EMS,IBOX
 SG_ CF_Gway_ALightStat : 37|1@1+ (1.0,0.0) [0.0|1.0] ""  AFLS,IBOX,LDWS_LKAS,AFLS,IBOX,LDWS_LKAS
 SG_ CF_Gway_LightSwState : 38|2@1+ (1.0,0.0) [0.0|3.0] ""  AFLS,IBOX,LDWS_LKAS,AFLS,IBOX,LDWS_LKAS
 SG_ CF_Gway_Frt_Fog_Act : 40|1@1+ (1.0,0.0) [0.0|1.0] ""  AFLS,CLU,IBOX,LDWS_LKAS,AFLS,IBOX,LDWS_LKAS
 SG_ CF_Gway_TSigRHSw : 41|1@1+ (1.0,0.0) [0.0|1.0] ""  IBOX,LDWS_LKAS,IBOX,LDWS_LKAS
 SG_ CF_Gway_TSigLHSw : 42|1@1+ (1.0,0.0) [0.0|1.0] ""  IBOX,LDWS_LKAS,IBOX,LDWS_LKAS
 SG_ CF_Gway_DriveTypeOption : 43|1@1+ (1.0,0.0) [0.0|1.0] ""  CLU,IBOX,LDWS_LKAS,IBOX,LDWS_LKAS
 SG_ CF_Gway_StarterRlyState : 44|1@1+ (1.0,0.0) [0.0|1.0] ""  EMS,IBOX,EMS,IBOX,SMK
 SG_ CF_Gway_PassiveAccessLock : 45|2@1+ (1.0,0.0) [0.0|7.0] ""  CLU,ECS,EMS,IBOX,ECS,EMS,IBOX,SMK
 SG_ CF_Gway_WiperMistSw : 47|1@1+ (1.0,0.0) [0.0|1.0] ""  CLU,EMS,IBOX,LDWS_LKAS
 SG_ CF_Gway_PassiveAccessUnlock : 48|2@1+ (1.0,0.0) [0.0|7.0] ""  CLU,ECS,EMS,IBOX,ECS,EMS,IBOX,SMK
 SG_ CF_Gway_RrSunRoofOpenState : 50|1@1+ (1.0,0.0) [0.0|1.0] ""  CLU,DATC,IBOX
 SG_ CF_Gway_PassingSW : 51|1@1+ (1.0,0.0) [0.0|1.0] ""  AFLS,IBOX,LDWS_LKAS,AFLS,IBOX,LDWS_LKAS
 SG_ CF_Gway_HBAControlMode : 52|1@1+ (1.0,0.0) [0.0|1.0] ""  IBOX,LDWS_LKAS,IBOX,LDWS_LKAS
 SG_ CF_Gway_HLpHighSw : 53|1@1+ (1.0,0.0) [0.0|1.0] ""  IBOX,LDWS_LKAS,IBOX,LDWS_LKAS
 SG_ CF_Gway_InhibitRMT : 54|2@1+ (1.0,0.0) [0.0|3.0] ""  EMS,EPB,ESC,IBOX,LCA,LDWS_LKAS,MDPS,PGS,SCC,SPAS,TPMS,EPB,ESC,IBOX,LCA,LDWS_LKAS,PGS,SCC,SPAS,TPMS
 SG_ CF_Gway_RainSnsOption : 56|1@1+ (1.0,0.0) [0.0|1.0] ""  CLU
 SG_ C_SunRoofOpenState : 57|1@1+ (1.0,0.0) [0.0|1.0] ""  CLU,DATC,IBOX,DATC,IBOX
 SG_ CF_Gway_Ign1 : 58|1@1+ (1.0,0.0) [0.0|1.0] ""  CLU
 SG_ CF_Gway_Ign2 : 59|1@1+ (1.0,0.0) [0.0|1.0] ""  CLU
 SG_ CF_Gway_ParkBrakeSw : 60|2@1+ (1.0,0.0) [0.0|3.0] ""  CLU,ESC,IBOX,SCC,ESC,IBOX,SCC
 SG_ CF_Gway_TurnSigRh : 62|2@1+ (1.0,0.0) [0.0|3.0] ""  CLU,EMS,IBOX,LCA,LDWS_LKAS,SCC,EMS,IBOX,LCA,LDWS_LKAS,SCC

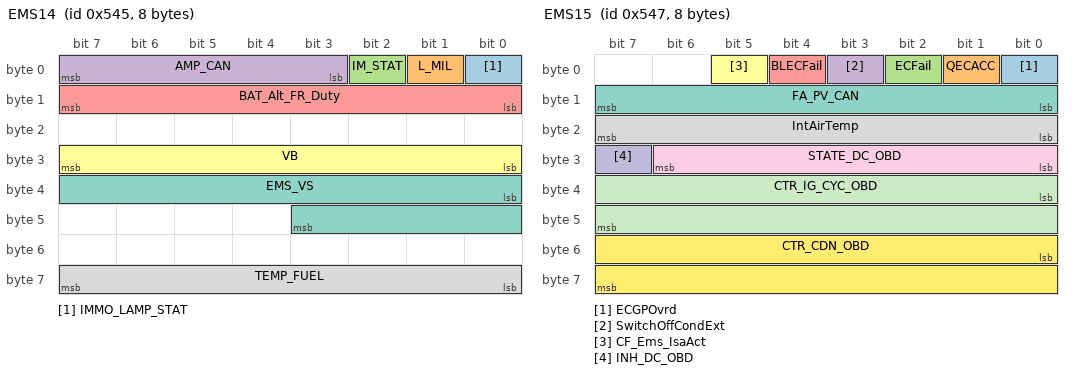
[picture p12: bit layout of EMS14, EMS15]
BO_ 1349 EMS14: 8 EMS
 SG_ IMMO_LAMP_STAT : 0|1@1+ (1.0,0.0) [0.0|1.0] ""  CLU,IBOX
 SG_ L_MIL : 1|1@1+ (1.0,0.0) [0.0|1.0] ""  CLU,CUBIS,IBOX
 SG_ IM_STAT : 2|1@1+ (1.0,0.0) [0.0|1.0] ""  CLU,IBOX
 SG_ AMP_CAN : 3|5@1+ (10.731613,458.98) [458.98|791.660003] "mmHg"  CLU,IBOX,TCU,TPMS
 SG_ BAT_Alt_FR_Duty : 8|8@1+ (0.4,0.0) [0.0|100.0] "%"  CGW,CUBIS,IBOX,TMU
 SG_ VB : 24|8@1+ (0.1015625,0.0) [0.0|25.8984375] "V"  CLU,CUBIS,DATC,EPB,FPCM,IBOX
 SG_ EMS_VS : 32|12@1+ (0.0625,0.0) [0.0|255.875] "km/h"  CLU
 SG_ TEMP_FUEL : 56|8@1+ (0.75,-48.0) [-48.0|143.25] "deg"  FPCM

BO_ 1351 EMS15: 8 EMS
 SG_ ECGPOvrd : 0|1@1+ (1.0,0.0) [0.0|1.0] ""  ESC,IBOX,SCC
 SG_ QECACC : 1|1@1+ (1.0,0.0) [0.0|1.0] ""  ESC,IBOX
 SG_ ECFail : 2|1@1+ (1.0,0.0) [0.0|1.0] ""  ESC,IBOX
 SG_ SwitchOffCondExt : 3|1@1+ (1.0,0.0) [0.0|1.0] ""  ESC,IBOX
 SG_ BLECFail : 4|1@1+ (1.0,0.0) [0.0|1.0] ""  ESC,IBOX
 SG_ CF_Ems_IsaAct : 5|1@1+ (1.0,0.0) [0.0|1.0] ""  CLU
 SG_ FA_PV_CAN : 8|8@1+ (0.3906,0.0) [0.0|99.2] "%"  IBOX,LDWS_LKAS,TCU
 SG_ IntAirTemp : 16|8@1+ (0.75,-48.0) [-48.0|143.25] "deg"  _4WD,ECS,EPB,IBOX,TCU
 SG_ STATE_DC_OBD : 24|7@1+ (1.0,0.0) [0.0|127.0] ""  IBOX,TCU
 SG_ INH_DC_OBD : 31|1@1+ (1.0,0.0) [0.0|1.0] ""  IBOX,TCU
 SG_ CTR_IG_CYC_OBD : 32|16@1+ (1.0,0.0) [0.0|65535.0] ""  ACU,IBOX,TCU
 SG_ CTR_CDN_OBD : 48|16@1+ (1.0,0.0) [0.0|65535.0] ""  IBOX,TCU

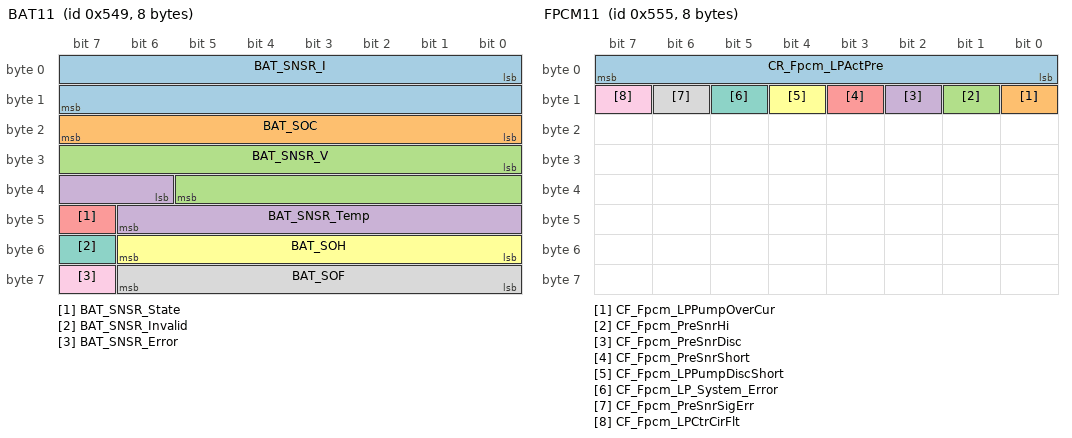
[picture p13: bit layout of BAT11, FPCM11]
BO_ 1353 BAT11: 8 EMS
 SG_ BAT_SNSR_I : 0|16@1+ (0.01,-327.0) [-327.0|328.0] "A"  CGW,CUBIS,IBOX,TMU
 SG_ BAT_SOC : 16|8@1+ (1.0,0.0) [0.0|100.0] "%"  CGW,CUBIS,IBOX,TMU
 SG_ BAT_SNSR_V : 24|14@1+ (0.0010,6.0) [6.0|18.0] "V"  CGW,CUBIS,IBOX,TMU
 SG_ BAT_SNSR_Temp : 38|9@1- (0.5,-40.0) [-40.0|125.0] "deg"  CGW,CUBIS,IBOX,TMU
 SG_ BAT_SNSR_State : 47|1@1+ (1.0,0.0) [0.0|1.0] ""  CGW,CUBIS,IBOX,TMU
 SG_ BAT_SOH : 48|7@1+ (1.0,0.0) [0.0|100.0] "%"  CGW,CUBIS,IBOX,TMU
 SG_ BAT_SNSR_Invalid : 55|1@1+ (1.0,0.0) [0.0|1.0] ""  CGW,CUBIS,IBOX,TMU
 SG_ BAT_SOF : 56|7@1+ (0.1,0.0) [0.0|12.0] "V"  CGW,CUBIS,IBOX,TMU
 SG_ BAT_SNSR_Error : 63|1@1+ (1.0,0.0) [0.0|1.0] ""  CGW,CUBIS,IBOX,TMU

BO_ 1363 CGW2: 8 BCM
 SG_ CF_Gway_GwayDiagState : 0|1@1+ (1.0,0.0) [0.0|3.0] ""  CLU,Dummy
 SG_ CF_Gway_DDMDiagState : 1|1@1+ (1.0,0.0) [0.0|1.0] ""  CLU,Dummy
 SG_ CF_Gway_SCMDiagState : 2|1@1+ (1.0,0.0) [0.0|1.0] ""  CLU,Dummy
 SG_ CF_Gway_PSMDiagState : 3|1@1+ (1.0,0.0) [0.0|1.0] ""  CLU,Dummy
 SG_ CF_Gway_SJBDiagState : 4|1@1+ (1.0,0.0) [0.0|1.0] ""  CLU,Dummy
 SG_ CF_Gway_IPMDiagState : 5|1@1+ (1.0,0.0) [0.0|1.0] ""  CLU,Dummy
 SG_ CF_Gway_LDMFail : 6|2@1+ (1.0,0.0) [0.0|3.0] ""  CLU,LDWS_LKAS,LDWS_LKAS
 SG_ CF_Gway_CLUSwGuiCtrl : 10|3@1+ (1.0,0.0) [0.0|63.0] ""  CLU,Dummy
 SG_ CF_Gway_CLUSwGroup : 13|1@1+ (1.0,0.0) [0.0|1.0] ""  CLU,Dummy
 SG_ CF_Gway_CLUSwMode : 14|1@1+ (1.0,0.0) [0.0|1.0] ""  CLU,Dummy
 SG_ CF_Gway_CLUSwEnter : 15|1@1+ (1.0,0.0) [0.0|1.0] ""  CLU,Dummy
 SG_ CF_Gway_AutoLightValue : 16|1@1+ (1.0,0.0) [0.0|1.0] ""  LCA,LCA
 SG_ CF_Gway_BrakeFluidSw : 17|1@1+ (1.0,0.0) [0.0|1.0] ""  CLU,Dummy
 SG_ CF_Gway_DrvSeatBeltInd : 18|2@1+ (1.0,0.0) [0.0|3.0] ""  CLU
 SG_ CF_Gway_AvTail : 20|1@1+ (1.0,0.0) [0.0|3.0] ""  CLU,SNV,SNV
 SG_ CF_Gway_RearFogAct : 21|1@1+ (1.0,0.0) [0.0|1.0] ""  CLU,Dummy
 SG_ CF_Gway_ExtTailAct : 22|1@1+ (1.0,0.0) [0.0|1.0] ""  AVM,CLU,LCA,PGS,SPAS,AVM,LCA,PGS,SPAS
 SG_ CF_Gway_RRDrSw : 23|1@1+ (1.0,0.0) [0.0|1.0] ""  CLU,Dummy
 SG_ CF_Gway_RLDrSw : 24|1@1+ (1.0,0.0) [0.0|1.0] ""  CLU,Dummy
 SG_ CF_Gway_IntTailAct : 25|1@1+ (1.0,0.0) [0.0|1.0] ""  CLU,Dummy
 SG_ CF_Gway_CountryCfg : 26|3@1+ (1.0,0.0) [0.0|7.0] ""  AVM,CLU,PGS,Dummy
 SG_ CF_Gway_WiperParkPosition : 32|1@1+ (1.0,0.0) [0.0|1.0] ""  AFLS,EMS,LDWS_LKAS,AFLS,EMS,LDWS_LKAS
 SG_ CF_Gway_HLLowLHFail : 33|1@1+ (1.0,0.0) [0.0|1.0] ""  LDWS_LKAS,SNV,LDWS_LKAS,SNV
 SG_ CF_Gway_HLLowRHFail : 34|1@1+ (1.0,0.0) [0.0|1.0] ""  LDWS_LKAS,SNV,LDWS_LKAS,SNV
 SG_ CF_Gway_ESCLFailWarn : 35|1@1+ (1.0,0.0) [0.0|1.0] ""  CLU,Dummy
 SG_ CF_Gway_ESCLNotLockedWarn : 36|1@1+ (1.0,0.0) [0.0|1.0] ""  CLU,Dummy
 SG_ CF_Gway_ESCLNotUnlockWarn : 37|1@1+ (1.0,0.0) [0.0|1.0] ""  CLU,Dummy
 SG_ CF_Gway_IDoutWarn : 38|1@1+ (1.0,0.0) [0.0|1.0] ""  CLU,Dummy
 SG_ CF_Gway_ImmoLp : 40|1@1+ (1.0,0.0) [0.0|3.0] ""  CLU,Dummy
 SG_ CF_Gway_BCMRKEID : 41|3@1+ (1.0,0.0) [0.0|7.0] ""  CLU,Dummy
 SG_ CF_Gway_VehicleNotPWarn : 44|1@1+ (1.0,0.0) [0.0|1.0] ""  CLU,Dummy
 SG_ CF_Gway_DeactivationWarn : 45|1@1+ (1.0,0.0) [0.0|1.0] ""  CLU,Dummy
 SG_ CF_Gway_KeyBATDischargeWarn : 46|1@1+ (1.0,0.0) [0.0|1.0] ""  CLU,Dummy
 SG_ CF_Gway_SSBWarn : 47|1@1+ (1.0,0.0) [0.0|1.0] ""  CLU,Dummy
 SG_ CF_Gway_SMKFobID : 48|3@1+ (1.0,0.0) [0.0|7.0] ""  CLU,Dummy
 SG_ CF_Gway_SMKRKECmd : 51|3@1+ (1.0,0.0) [0.0|7.0] ""  CLU,Dummy
 SG_ CF_Gway_AutoLightOption : 54|1@1+ (1.0,0.0) [0.0|1.0] ""  CLU
 SG_ CF_Gway_SJBDeliveryMode : 55|1@1+ (1.0,0.0) [0.0|1.0] ""  CLU,Dummy
 SG_ CF_Gway_KeyoutLp : 56|1@1+ (1.0,0.0) [0.0|1.0] ""  CLU,Dummy
 SG_ CF_Gway_SMKDispWarn : 57|4@1+ (1.0,0.0) [0.0|15.0] ""  CLU,Dummy
 SG_ CF_Gway_WngBuz : 61|3@1+ (1.0,0.0) [0.0|7.0] ""  CLU,Dummy

BO_ 1365 FPCM11: 8 FPCM
 SG_ CR_Fpcm_LPActPre : 0|8@1+ (3.137254902,0.0) [0.0|800.0] "kPa"  EMS
 SG_ CF_Fpcm_LPPumpOverCur : 8|1@1+ (1.0,0.0) [0.0|1.0] ""  EMS
 SG_ CF_Fpcm_PreSnrHi : 9|1@1+ (1.0,0.0) [0.0|1.0] ""  EMS
 SG_ CF_Fpcm_PreSnrDisc : 10|1@1+ (1.0,0.0) [0.0|1.0] ""  EMS
 SG_ CF_Fpcm_PreSnrShort : 11|1@1+ (1.0,0.0) [0.0|1.0] ""  EMS
 SG_ CF_Fpcm_LPPumpDiscShort : 12|1@1+ (1.0,0.0) [0.0|1.0] ""  EMS
 SG_ CF_Fpcm_LP_System_Error : 13|1@1+ (1.0,0.0) [0.0|1.0] ""  EMS
 SG_ CF_Fpcm_PreSnrSigErr : 14|1@1+ (1.0,0.0) [0.0|1.0] ""  EMS
 SG_ CF_Fpcm_LPCtrCirFlt : 15|1@1+ (1.0,0.0) [0.0|1.0] ""  EMS

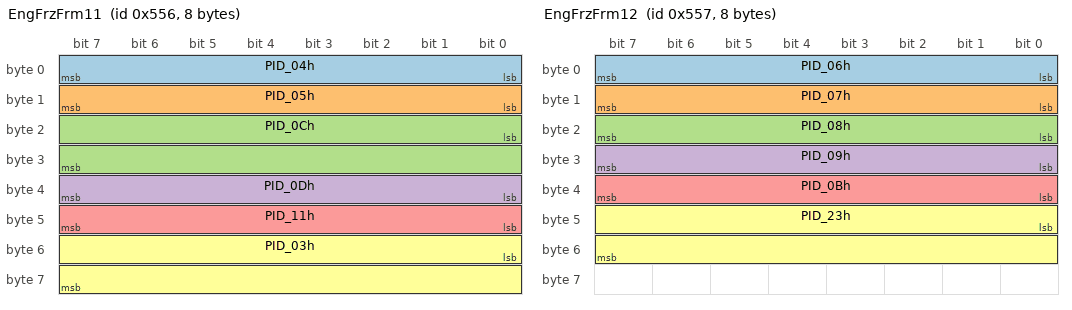
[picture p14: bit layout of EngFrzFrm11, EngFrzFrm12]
BO_ 1366 EngFrzFrm11: 8 EMS
 SG_ PID_04h : 0|8@1+ (0.3921568627,0.0) [0.0|100.0] "%"  AAF,TCU
 SG_ PID_05h : 8|8@1+ (1.0,-40.0) [-40.0|215.0] "deg"  AAF,TCU
 SG_ PID_0Ch : 16|16@1+ (0.25,0.0) [0.0|16383.75] "rpm"  AAF,TCU
 SG_ PID_0Dh : 32|8@1+ (1.0,0.0) [0.0|255.0] "km/h"  AAF,TCU
 SG_ PID_11h : 40|8@1+ (0.3921568627,0.0) [0.0|100.0] "%"  AAF,TCU
 SG_ PID_03h : 48|16@1+ (1.0,0.0) [0.0|65535.0] ""  AAF,TCU

BO_ 1367 EngFrzFrm12: 8 EMS
 SG_ PID_06h : 0|8@1+ (0.78125,-100.0) [-100.0|99.22] "%"  AAF,IBOX,TCU
 SG_ PID_07h : 8|8@1+ (0.78125,-100.0) [-100.0|99.22] "%"  AAF,IBOX,TCU
 SG_ PID_08h : 16|8@1+ (0.78125,-100.0) [-100.0|99.22] "%"  AAF,IBOX,TCU
 SG_ PID_09h : 24|8@1+ (0.78125,-100.0) [-100.0|99.22] "%"  AAF,IBOX,TCU
 SG_ PID_0Bh : 32|8@1+ (1.0,0.0) [0.0|255.0] "kPa"  AAF,IBOX,TCU
 SG_ PID_23h : 40|16@1+ (10.0,0.0) [0.0|655350.0] "kPa"  AAF,IBOX,TCU

BO_ 1369 CGW4: 8 BCM
 SG_ CF_Gway_MemoryP1Cmd : 0|1@1+ (1.0,0.0) [0.0|1.0] ""  CLU
 SG_ CF_Gway_MemoryP2Cmd : 1|1@1+ (1.0,0.0) [0.0|1.0] ""  CLU
 SG_ CF_Gway_PBackP1Cmd : 2|1@1+ (1.0,0.0) [0.0|1.0] ""  CLU
 SG_ CF_Gway_PBackP2Cmd : 3|1@1+ (1.0,0.0) [0.0|1.0] ""  CLU
 SG_ CF_Gway_StrgWhlHeatedState : 4|1@1+ (1.0,0.0) [0.0|1.0] ""  CLU
 SG_ CF_Gway_PBackStopCmd : 5|1@1+ (1.0,0.0) [0.0|1.0] ""  CLU,HUD
 SG_ CF_Gway_StaticBendLhAct : 6|1@1+ (1.0,0.0) [0.0|1.0] ""  CLU
 SG_ CF_Gway_StaticBendRhAct : 7|1@1+ (1.0,0.0) [0.0|1.0] ""  CLU
 SG_ CF_Gway_DrvWdwStat : 8|1@1+ (1.0,0.0) [0.0|1.0] ""  CLU
 SG_ CF_Gway_RLWdwState : 9|1@1+ (1.0,0.0) [0.0|1.0] ""  CLU
 SG_ CF_Gway_RRWdwState : 10|1@1+ (1.0,0.0) [0.0|1.0] ""  CLU
 SG_ CF_Gway_AstWdwStat : 11|1@1+ (1.0,0.0) [0.0|1.0] ""  CLU
 SG_ CF_Gway_MemoryEnable : 12|1@1+ (1.0,0.0) [0.0|1.0] ""  CLU
 SG_ CF_Gway_PBACKStopCmd : 13|1@1+ (1.0,0.0) [0.0|1.0] ""  CLU
 SG_ CF_Gway_PBACKStop : 14|1@1+ (1.0,0.0) [0.0|1.0] ""  CLU,HUD
 SG_ CF_Gway_IMSBuzzer : 15|1@1+ (1.0,0.0) [0.0|1.0] ""  CLU
 SG_ CF_Gway_DrvSeatBeltInd : 36|2@1+ (1.0,0.0) [0.0|3.0] ""  CLU,Dummy
 SG_ CF_Gway_AstSeatBeltInd : 38|2@1+ (1.0,0.0) [0.0|3.0] ""  CLU
 SG_ CF_Gway_RCSeatBeltInd : 40|2@1+ (1.0,0.0) [0.0|3.0] ""  CLU
 SG_ CF_Gway_RLSeatBeltInd : 42|2@1+ (1.0,0.0) [0.0|3.0] ""  CLU
 SG_ CF_Gway_RRSeatBeltInd : 44|2@1+ (1.0,0.0) [0.0|3.0] ""  CLU
 SG_ CF_Gway_RrWiperHighSw : 46|1@1+ (1.0,0.0) [0.0|1.0] ""  CLU
 SG_ CF_Gway_RrWiperLowSw : 47|1@1+ (1.0,0.0) [0.0|1.0] ""  CLU

BO_ 1407 HU_MON_PE_01: 8 CLU
 SG_ HU_Type : 0|8@1+ (1.0,0.0) [0.0|255.0] ""  AVM,PGS

BO_ 1414 EVP11: 3 EVP
 SG_ CF_Evp_Stat : 0|1@1+ (1.0,0.0) [0.0|1.0] ""  CLU

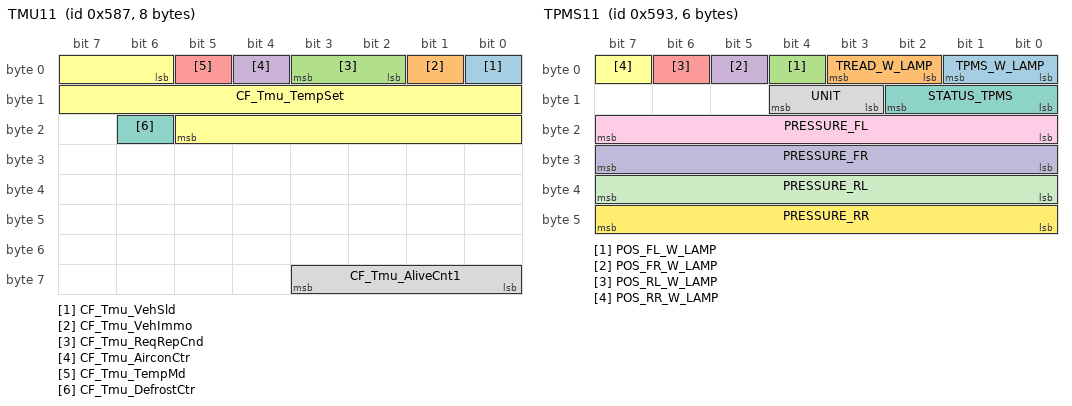
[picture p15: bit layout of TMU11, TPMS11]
BO_ 1415 TMU11: 8 IBOX
 SG_ CF_Tmu_VehSld : 0|1@1+ (1.0,0.0) [0.0|1.0] ""  EMS
 SG_ CF_Tmu_VehImmo : 1|1@1+ (1.0,0.0) [0.0|1.0] ""  EMS
 SG_ CF_Tmu_ReqRepCnd : 2|2@1+ (1.0,0.0) [0.0|3.0] ""  EMS
 SG_ CF_Tmu_AirconCtr : 4|1@1+ (1.0,0.0) [0.0|1.0] ""  DATC
 SG_ CF_Tmu_TempMd : 5|1@1+ (1.0,0.0) [0.0|1.0] ""  DATC
 SG_ CF_Tmu_TempSet : 6|16@1+ (1.0,0.0) [0.0|20.0] ""  DATC
 SG_ CF_Tmu_DefrostCtr : 22|1@1+ (1.0,0.0) [0.0|1.0] ""  DATC,FATC
 SG_ CF_Tmu_AliveCnt1 : 56|4@1+ (1.0,0.0) [0.0|15.0] ""  EMS

BO_ 1419 LCA11: 8 LCA
 SG_ CF_Lca_Stat : 0|4@1+ (1.0,0.0) [0.0|15.0] ""  BCM,CLU
 SG_ CF_Rcta_Stat : 4|4@1+ (1.0,0.0) [0.0|15.0] ""  BCM,CLU
 SG_ CF_Lca_IndLeft : 8|2@1+ (1.0,0.0) [0.0|3.0] ""  BCM,CLU
 SG_ CF_Rcw_Stat : 10|4@1+ (1.0,0.0) [0.0|15.0] ""  BCM,CLU
 SG_ CF_RCW_Warning : 14|2@1+ (1.0,0.0) [0.0|3.0] ""  BCM,CLU
 SG_ CF_Lca_IndRight : 16|2@1+ (1.0,0.0) [0.0|3.0] ""  BCM,CLU
 SG_ CF_Lca_SndWan_Stat : 18|2@1+ (1.0,0.0) [0.0|3.0] ""  BCM,CLU
 SG_ CF_FR_SndWan : 20|1@1+ (1.0,0.0) [0.0|1.0] ""  BCM,CLU
 SG_ CF_FL_SndWan : 21|1@1+ (1.0,0.0) [0.0|1.0] ""  BCM,CLU
 SG_ CF_RR_SndWan : 22|1@1+ (1.0,0.0) [0.0|1.0] ""  BCM,CLU
 SG_ CF_RL_SndWan : 23|1@1+ (1.0,0.0) [0.0|1.0] ""  BCM,CLU
 SG_ CF_Lca_IndBriLeft : 24|8@1+ (1.0,0.0) [0.0|255.0] ""  BCM,CLU
 SG_ CF_Lca_IndBriRight : 32|8@1+ (1.0,0.0) [0.0|255.0] ""  BCM,CLU
 SG_ CF_RCTA_IndBriLeft : 40|8@1+ (1.0,0.0) [0.0|255.0] ""  BCM,CLU
 SG_ CF_RCTA_IndBriRight : 48|8@1+ (1.0,0.0) [0.0|255.0] ""  BCM,CLU
 SG_ CF_RCTA_IndLeft : 56|2@1+ (1.0,0.0) [0.0|3.0] ""  BCM,CLU
 SG_ CF_RCTA_IndRight : 58|2@1+ (1.0,0.0) [0.0|3.0] ""  BCM,CLU
 SG_ CF_SndWarnForClu : 60|1@1+ (1.0,0.0) [0.0|1.0] ""  CLU

BO_ 1427 TPMS11: 6 BCM
 SG_ TPMS_W_LAMP : 0|2@1+ (1.0,0.0) [0.0|3.0] ""  CLU,CUBIS,HUD,IBOX,CLU,CUBIS,HUD,IBOX
 SG_ TREAD_W_LAMP : 2|2@1+ (1.0,0.0) [0.0|3.0] ""  CLU,CUBIS,HUD,IBOX,CLU,CUBIS,HUD,IBOX
 SG_ POS_FL_W_LAMP : 4|1@1+ (1.0,0.0) [0.0|1.0] ""  CLU,CUBIS,HUD,IBOX
 SG_ POS_FR_W_LAMP : 5|1@1+ (1.0,0.0) [0.0|1.0] ""  CLU,CUBIS,HUD,IBOX
 SG_ POS_RL_W_LAMP : 6|1@1+ (1.0,0.0) [0.0|1.0] ""  CLU,CUBIS,HUD,IBOX
 SG_ POS_RR_W_LAMP : 7|1@1+ (1.0,0.0) [0.0|1.0] ""  CLU,CUBIS,HUD,IBOX
 SG_ STATUS_TPMS : 8|3@1+ (1.0,0.0) [0.0|0.0] ""  CLU
 SG_ UNIT : 11|2@1+ (1.0,0.0) [0.0|3.0] ""  CLU
 SG_ PRESSURE_FL : 16|8@1+ (1.0,0.0) [0.0|255.0] ""  CLU
 SG_ PRESSURE_FR : 24|8@1+ (1.0,0.0) [0.0|255.0] ""  CLU
 SG_ PRESSURE_RL : 32|8@1+ (1.0,0.0) [0.0|255.0] ""  CLU
 SG_ PRESSURE_RR : 40|8@1+ (1.0,0.0) [0.0|255.0] ""  CLU

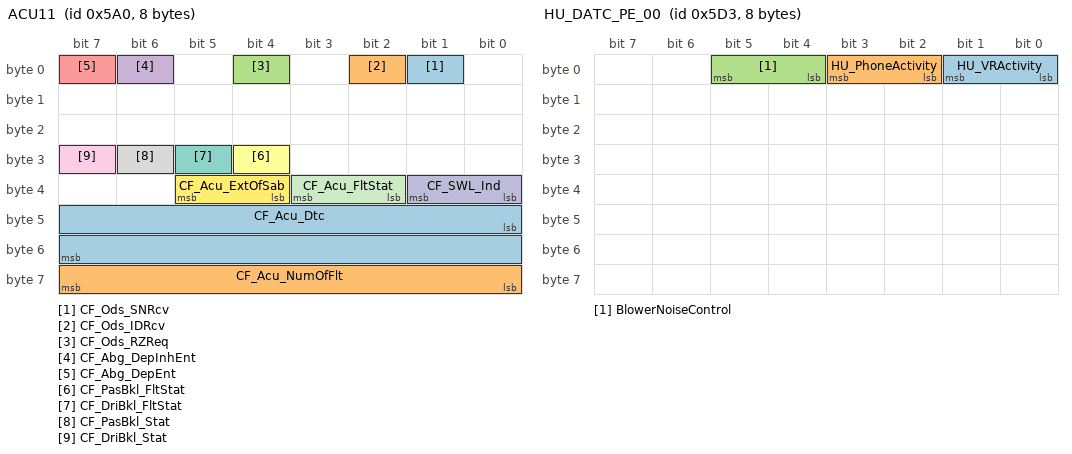
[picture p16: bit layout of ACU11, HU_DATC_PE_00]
BO_ 1440 ACU11: 8 ACU
 SG_ CF_Ods_SNRcv : 1|1@1+ (1.0,0.0) [0.0|1.0] ""  ODS
 SG_ CF_Ods_IDRcv : 2|1@1+ (1.0,0.0) [0.0|1.0] ""  ODS
 SG_ CF_Ods_RZReq : 4|1@1+ (1.0,0.0) [0.0|1.0] ""  ODS
 SG_ CF_Abg_DepInhEnt : 6|1@1+ (1.0,0.0) [0.0|1.0] ""  ODS
 SG_ CF_Abg_DepEnt : 7|1@1+ (1.0,0.0) [0.0|1.0] ""  ODS
 SG_ CF_PasBkl_FltStat : 28|1@1+ (1.0,0.0) [0.0|1.0] ""  ODS,PSB
 SG_ CF_DriBkl_FltStat : 29|1@1+ (1.0,0.0) [0.0|1.0] ""  ODS,PSB
 SG_ CF_PasBkl_Stat : 30|1@1+ (1.0,0.0) [0.0|1.0] ""  IBOX,ODS,PSB,TMU
 SG_ CF_DriBkl_Stat : 31|1@1+ (1.0,0.0) [0.0|1.0] ""  ODS,PSB
 SG_ CF_SWL_Ind : 32|2@1+ (1.0,0.0) [0.0|3.0] ""  CUBIS,IBOX
 SG_ CF_Acu_FltStat : 34|2@1+ (1.0,0.0) [0.0|3.0] ""  CUBIS,IBOX
 SG_ CF_Acu_ExtOfSab : 36|2@1+ (1.0,0.0) [0.0|3.0] ""  BCM,CLU,CUBIS,IBOX
 SG_ CF_Acu_Dtc : 40|16@1+ (1.0,0.0) [0.0|65535.0] ""  CUBIS,IBOX
 SG_ CF_Acu_NumOfFlt : 56|8@1+ (1.0,0.0) [0.0|255.0] ""  CUBIS,IBOX

BO_ 1456 CLU12: 4 CLU
 SG_ CF_Clu_Odometer : 0|24@1+ (0.1,0.0) [0.0|1677721.4] "km"  _4WD,AAF,BCM,CUBIS,EMS,EPB,IBOX,LDWS_LKAS,SCC,TPMS

BO_ 1460 ???: 8 ???

BO_ 1486 ???: 8 ???

BO_ 1487 ???: 8 ???
 SG_ Fuel_Level : 40|8@1+ (0.392156862745098,0.0) [0.0|100] "%"  _???

BO_ 1491 HU_DATC_PE_00: 8 CLU
 SG_ HU_VRActivity : 0|2@1+ (1.0,0.0) [0.0|3.0] ""  DATC
 SG_ HU_PhoneActivity : 2|2@1+ (1.0,0.0) [0.0|3.0] ""  DATC
 SG_ BlowerNoiseControl : 4|2@1+ (1.0,0.0) [0.0|3.0] ""  DATC

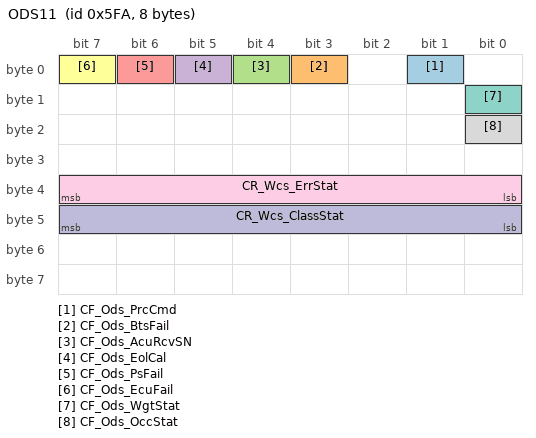
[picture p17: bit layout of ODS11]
BO_ 1530 ODS11: 8 ODS
 SG_ CF_Ods_PrcCmd : 1|1@1+ (1.0,0.0) [0.0|1.0] ""  Dummy
 SG_ CF_Ods_BtsFail : 3|1@1+ (1.0,0.0) [0.0|1.0] ""  Dummy
 SG_ CF_Ods_AcuRcvSN : 4|1@1+ (1.0,0.0) [0.0|1.0] ""  ACU
 SG_ CF_Ods_EolCal : 5|1@1+ (1.0,0.0) [0.0|1.0] ""  ACU
 SG_ CF_Ods_PsFail : 6|1@1+ (1.0,0.0) [0.0|1.0] ""  ACU
 SG_ CF_Ods_EcuFail : 7|1@1+ (1.0,0.0) [0.0|1.0] ""  ACU
 SG_ CF_Ods_WgtStat : 8|1@1+ (1.0,0.0) [0.0|1.0] ""  ACU
 SG_ CF_Ods_OccStat : 16|1@1+ (1.0,0.0) [0.0|1.0] ""  ACU
 SG_ CR_Wcs_ErrStat : 32|8@1+ (1.0,0.0) [0.0|63.0] ""  ACU
 SG_ CR_Wcs_ClassStat : 40|8@1+ (1.0,0.0) [0.0|4.0] ""  ACU,BCM

BO_ 1952 ???: 8 ???

BO_ 1960 ???: 8 ???

BO_ 1988 ???: 8 ???

BO_ 1996 ???: 8 ???

BO_ 2001 ???: 8 ???

BO_ 2004 ???: 8 ???

BO_ 2009 ???: 8 ???

BO_ 2012 ???: 8 ???

BO_ 2016 ???: 8 ???

BO_ 2017 ???: 8 ???

BO_ 2024 ???: 8 ???
